VERSION ""

NS_ :

BS_:

BU_: WirelessCharger_1 WirelessChargerTemplate Applications OnBoardCharger_1 OnBoardChargerTemplate PowerModule_6 PowerModule_5 PowerModule_4 PowerModule_3 PowerModule_10 PowerModule_1 PowerModule_7 PowerModule_8 PowerModule_9 PowerModule_2 PowerModuleTemplate SystemController
VAL_TABLE_ CAN_BAUD 3 "1M" 2 "500K" 1 "250K" 0 "125K" ;
VAL_TABLE_ ConfigHwCodes 1 "P" 0 "N/A" ;
VAL_TABLE_ BL_ctrl 1 "Unlock" 0 "Reset" ;
VAL_TABLE_ BL_ACK 204 "ACK" 51 "NAK" ;
VAL_TABLE_ CalibStatus 12 "FAILED_TO_SAVE" 11 "RESET_TO_DEFAULT_VALUES" 10 "CALIBRATED" 9 "SCALE_AND_OFFSET_CALCULATED" 8 "ALL_MEASUREMENTS_GATHERED" 7 "INVALID_MEASUREMENT_POINT" 6 "V_HIGH_MEAS_GATHERED" 5 "V_LOW_MEAS_GATHERED" 3 "I_MID_MEAS_GATHERED" 4 "I_HIGH_MEAS_GATHERED" 2 "I_LOW_MEAS_GATHERED" 1 "WAITING_FOR_MEASUREMENTS" 0 "UNCALIBRATED" ;
VAL_TABLE_ CalibMeasType 1 "Current" 0 "Voltage" ;
VAL_TABLE_ OkAlert 1 "ALERT" 0 "OK" ;
VAL_TABLE_ YesNo 1 "YES" 0 "NO" ;
VAL_TABLE_ OkFault 1 "FAULT" 0 "OK" ;
VAL_TABLE_ OnOff 1 "ON" 0 "OFF" ;
VAL_TABLE_ ModuleState 16 "error" 4 "run" 1 "standby" ;
VAL_TABLE_ Status 1 "Ready" 0 "Not Ready" ;

BO_ 592 FanControl: 1 Applications
 SG_ FanControlSpeed : 0|8@1+ (1,0) [0|100] "%"  PowerModule_9,PowerModule_8,PowerModule_7,PowerModule_6,PowerModule_5,PowerModule_4,PowerModule_3,PowerModule_2,PowerModule_10,PowerModule_1,PowerModuleTemplate

BO_ 1920 Config_CAN: 1 Applications
 SG_ Config_Baud : 0|4@1+ (1,0) [0|15] "ENUM"  WirelessCharger_1,WirelessChargerTemplate

BO_ 1994 FirmwareFamilyReport_10: 4 PowerModule_10
 SG_ Firmware_Variant : 16|16@1+ (1,0) [0|0] ""  SystemController,Applications
 SG_ Firmware_Family : 0|16@1+ (1,0) [0|0] ""  SystemController,Applications

BO_ 1993 FirmwareFamilyReport_9: 4 PowerModule_9
 SG_ Firmware_Variant : 16|16@1+ (1,0) [0|0] ""  SystemController,Applications
 SG_ Firmware_Family : 0|16@1+ (1,0) [0|0] ""  SystemController,Applications

BO_ 1992 FirmwareFamilyReport_8: 4 PowerModule_8
 SG_ Firmware_Variant : 16|16@1+ (1,0) [0|0] ""  SystemController,Applications
 SG_ Firmware_Family : 0|16@1+ (1,0) [0|0] ""  SystemController,Applications

BO_ 1991 FirmwareFamilyReport_7: 4 PowerModule_7
 SG_ Firmware_Variant : 16|16@1+ (1,0) [0|0] ""  SystemController,Applications
 SG_ Firmware_Family : 0|16@1+ (1,0) [0|0] ""  SystemController,Applications

BO_ 1990 FirmwareFamilyReport_6: 4 PowerModule_6
 SG_ Firmware_Variant : 16|16@1+ (1,0) [0|0] ""  SystemController,Applications
 SG_ Firmware_Family : 0|16@1+ (1,0) [0|0] ""  SystemController,Applications

BO_ 1989 FirmwareFamilyReport_5: 4 PowerModule_5
 SG_ Firmware_Variant : 16|16@1+ (1,0) [0|0] ""  SystemController,Applications
 SG_ Firmware_Family : 0|16@1+ (1,0) [0|0] ""  SystemController,Applications

BO_ 1988 FirmwareFamilyReport_4: 4 PowerModule_4
 SG_ Firmware_Variant : 16|16@1+ (1,0) [0|0] ""  SystemController,Applications
 SG_ Firmware_Family : 0|16@1+ (1,0) [0|0] ""  SystemController,Applications

BO_ 1987 FirmwareFamilyReport_3: 4 PowerModule_3
 SG_ Firmware_Variant : 16|16@1+ (1,0) [0|0] ""  SystemController,Applications
 SG_ Firmware_Family : 0|16@1+ (1,0) [0|0] ""  SystemController,Applications

BO_ 1986 FirmwareFamilyReport_2: 4 PowerModule_2
 SG_ Firmware_Variant : 16|16@1+ (1,0) [0|0] ""  SystemController,Applications
 SG_ Firmware_Family : 0|16@1+ (1,0) [0|0] ""  SystemController,Applications

BO_ 1985 FirmwareFamilyReport_1: 4 OnBoardCharger_1
 SG_ Firmware_Variant : 16|16@1+ (1,0) [0|0] ""  SystemController,Applications
 SG_ Firmware_Family : 0|16@1+ (1,0) [0|0] ""  SystemController,Applications

BO_ 1121 ChargerTimeReport_1: 4 OnBoardCharger_1
 SG_ ChargerTimeReport : 0|32@1+ (1,0) [0|0] "seconds"  Applications

BO_ 1122 ChargerTimeReport_2: 4 Vector__XXX
 SG_ ChargerTimeReport : 0|32@1+ (1,0) [0|0] "seconds"  Applications

BO_ 1123 ChargerTimeReport_3: 4 Vector__XXX
 SG_ ChargerTimeReport : 0|32@1+ (1,0) [0|0] "seconds"  Applications

BO_ 1124 ChargerTimeReport_4: 4 Vector__XXX
 SG_ ChargerTimeReport : 0|32@1+ (1,0) [0|0] "seconds"  Applications

BO_ 1125 ChargerTimeReport_5: 4 Vector__XXX
 SG_ ChargerTimeReport : 0|32@1+ (1,0) [0|0] "seconds"  Applications

BO_ 1126 ChargerTimeReport_6: 4 Vector__XXX
 SG_ ChargerTimeReport : 0|32@1+ (1,0) [0|0] "seconds"  Applications

BO_ 1127 ChargerTimeReport_7: 4 Vector__XXX
 SG_ ChargerTimeReport : 0|32@1+ (1,0) [0|0] "seconds"  Applications

BO_ 1128 ChargerTimeReport_8: 4 Vector__XXX
 SG_ ChargerTimeReport : 0|32@1+ (1,0) [0|0] "seconds"  Applications

BO_ 1129 ChargerTimeReport_9: 4 Vector__XXX
 SG_ ChargerTimeReport : 0|32@1+ (1,0) [0|0] "seconds"  Applications

BO_ 1130 ChargerTimeReport_10: 4 Vector__XXX
 SG_ ChargerTimeReport : 0|32@1+ (1,0) [0|0] "seconds"  Applications

BO_ 1120 ChargerTimeReport_T: 4 OnBoardChargerTemplate
 SG_ ChargerTimeReport : 0|32@1+ (1,0) [0|0] "seconds" Vector__XXX

BO_ 1104 Config_SetChargerTime: 4 Applications
 SG_ ChargerTimeConfig : 0|32@1+ (1,0) [0|0] "seconds"  OnBoardCharger_1,OnBoardChargerTemplate

BO_ 1089 ProfileDeleteReport_1: 2 OnBoardCharger_1
 SG_ ProfileDeleteReport_Status : 8|8@1+ (1,0) [0|0] ""  Applications
 SG_ ProfileDeleteReport_Index : 0|8@1+ (1,0) [0|0] ""  Applications

BO_ 1090 ProfileDeleteReport_2: 2 Vector__XXX
 SG_ ProfileDeleteReport_Status : 8|8@1+ (1,0) [0|0] ""  Applications
 SG_ ProfileDeleteReport_Index : 0|8@1+ (1,0) [0|0] ""  Applications

BO_ 1091 ProfileDeleteReport_3: 2 Vector__XXX
 SG_ ProfileDeleteReport_Status : 8|8@1+ (1,0) [0|0] ""  Applications
 SG_ ProfileDeleteReport_Index : 0|8@1+ (1,0) [0|0] ""  Applications

BO_ 1092 ProfileDeleteReport_4: 2 Vector__XXX
 SG_ ProfileDeleteReport_Status : 8|8@1+ (1,0) [0|0] ""  Applications
 SG_ ProfileDeleteReport_Index : 0|8@1+ (1,0) [0|0] ""  Applications

BO_ 1093 ProfileDeleteReport_5: 2 Vector__XXX
 SG_ ProfileDeleteReport_Status : 8|8@1+ (1,0) [0|0] ""  Applications
 SG_ ProfileDeleteReport_Index : 0|8@1+ (1,0) [0|0] ""  Applications

BO_ 1094 ProfileDeleteReport_6: 2 Vector__XXX
 SG_ ProfileDeleteReport_Status : 8|8@1+ (1,0) [0|0] ""  Applications
 SG_ ProfileDeleteReport_Index : 0|8@1+ (1,0) [0|0] ""  Applications

BO_ 1095 ProfileDeleteReport_7: 2 Vector__XXX
 SG_ ProfileDeleteReport_Status : 8|8@1+ (1,0) [0|0] ""  Applications
 SG_ ProfileDeleteReport_Index : 0|8@1+ (1,0) [0|0] ""  Applications

BO_ 1096 ProfileDeleteReport_8: 2 Vector__XXX
 SG_ ProfileDeleteReport_Status : 8|8@1+ (1,0) [0|0] ""  Applications
 SG_ ProfileDeleteReport_Index : 0|8@1+ (1,0) [0|0] ""  Applications

BO_ 1097 ProfileDeleteReport_9: 2 Vector__XXX
 SG_ ProfileDeleteReport_Status : 8|8@1+ (1,0) [0|0] ""  Applications
 SG_ ProfileDeleteReport_Index : 0|8@1+ (1,0) [0|0] ""  Applications

BO_ 1098 ProfileDeleteReport_10: 2 Vector__XXX
 SG_ ProfileDeleteReport_Status : 8|8@1+ (1,0) [0|0] ""  Applications
 SG_ ProfileDeleteReport_Index : 0|8@1+ (1,0) [0|0] ""  Applications

BO_ 1088 ProfileDeleteReport_T: 2 OnBoardChargerTemplate
 SG_ ProfileDeleteReport_Status : 8|8@1+ (1,0) [0|0] "" Vector__XXX
 SG_ ProfileDeleteReport_Index : 0|8@1+ (1,0) [0|0] "" Vector__XXX

BO_ 1072 ProfileDeleteRequest: 1 Applications
 SG_ ProfileDelete_Index : 0|8@1+ (1,0) [0|0] ""  OnBoardCharger_1,OnBoardChargerTemplate

BO_ 1057 ProfileIdReport_1: 7 OnBoardCharger_1
 SG_ ProfileReport_Status : 0|8@1+ (1,0) [0|0] ""  Applications
 SG_ ProfileReport_MaxIndex : 16|8@1+ (1,0) [0|0] ""  Applications
 SG_ ProfileReport_Index : 8|8@1+ (1,0) [0|0] ""  Applications
 SG_ ProfileReport_Id : 24|32@1+ (1,0) [0|0] ""  Applications

BO_ 1058 ProfileIdReport_2: 7 Vector__XXX
 SG_ ProfileReport_Status : 0|8@1+ (1,0) [0|0] ""  Applications
 SG_ ProfileReport_MaxIndex : 16|8@1+ (1,0) [0|0] ""  Applications
 SG_ ProfileReport_Index : 8|8@1+ (1,0) [0|0] ""  Applications
 SG_ ProfileReport_Id : 24|32@1+ (1,0) [0|0] ""  Applications

BO_ 1059 ProfileIdReport_3: 7 Vector__XXX
 SG_ ProfileReport_Status : 0|8@1+ (1,0) [0|0] ""  Applications
 SG_ ProfileReport_MaxIndex : 16|8@1+ (1,0) [0|0] ""  Applications
 SG_ ProfileReport_Index : 8|8@1+ (1,0) [0|0] ""  Applications
 SG_ ProfileReport_Id : 24|32@1+ (1,0) [0|0] ""  Applications

BO_ 1060 ProfileIdReport_4: 7 Vector__XXX
 SG_ ProfileReport_Status : 0|8@1+ (1,0) [0|0] ""  Applications
 SG_ ProfileReport_MaxIndex : 16|8@1+ (1,0) [0|0] ""  Applications
 SG_ ProfileReport_Index : 8|8@1+ (1,0) [0|0] ""  Applications
 SG_ ProfileReport_Id : 24|32@1+ (1,0) [0|0] ""  Applications

BO_ 1061 ProfileIdReport_5: 7 Vector__XXX
 SG_ ProfileReport_Status : 0|8@1+ (1,0) [0|0] ""  Applications
 SG_ ProfileReport_MaxIndex : 16|8@1+ (1,0) [0|0] ""  Applications
 SG_ ProfileReport_Index : 8|8@1+ (1,0) [0|0] ""  Applications
 SG_ ProfileReport_Id : 24|32@1+ (1,0) [0|0] ""  Applications

BO_ 1062 ProfileIdReport_6: 7 Vector__XXX
 SG_ ProfileReport_Status : 0|8@1+ (1,0) [0|0] ""  Applications
 SG_ ProfileReport_MaxIndex : 16|8@1+ (1,0) [0|0] ""  Applications
 SG_ ProfileReport_Index : 8|8@1+ (1,0) [0|0] ""  Applications
 SG_ ProfileReport_Id : 24|32@1+ (1,0) [0|0] ""  Applications

BO_ 1063 ProfileIdReport_7: 7 Vector__XXX
 SG_ ProfileReport_Status : 0|8@1+ (1,0) [0|0] ""  Applications
 SG_ ProfileReport_MaxIndex : 16|8@1+ (1,0) [0|0] ""  Applications
 SG_ ProfileReport_Index : 8|8@1+ (1,0) [0|0] ""  Applications
 SG_ ProfileReport_Id : 24|32@1+ (1,0) [0|0] ""  Applications

BO_ 1064 ProfileIdReport_8: 7 Vector__XXX
 SG_ ProfileReport_Status : 0|8@1+ (1,0) [0|0] ""  Applications
 SG_ ProfileReport_MaxIndex : 16|8@1+ (1,0) [0|0] ""  Applications
 SG_ ProfileReport_Index : 8|8@1+ (1,0) [0|0] ""  Applications
 SG_ ProfileReport_Id : 24|32@1+ (1,0) [0|0] ""  Applications

BO_ 1065 ProfileIdReport_9: 7 Vector__XXX
 SG_ ProfileReport_Status : 0|8@1+ (1,0) [0|0] ""  Applications
 SG_ ProfileReport_MaxIndex : 16|8@1+ (1,0) [0|0] ""  Applications
 SG_ ProfileReport_Index : 8|8@1+ (1,0) [0|0] ""  Applications
 SG_ ProfileReport_Id : 24|32@1+ (1,0) [0|0] ""  Applications

BO_ 1066 ProfileIdReport_10: 7 Vector__XXX
 SG_ ProfileReport_Status : 0|8@1+ (1,0) [0|0] ""  Applications
 SG_ ProfileReport_MaxIndex : 16|8@1+ (1,0) [0|0] ""  Applications
 SG_ ProfileReport_Index : 8|8@1+ (1,0) [0|0] ""  Applications
 SG_ ProfileReport_Id : 24|32@1+ (1,0) [0|0] ""  Applications

BO_ 1056 ProfileIdReport_T: 7 OnBoardChargerTemplate
 SG_ ProfileReport_Status : 0|8@1+ (1,0) [0|0] "" Vector__XXX
 SG_ ProfileReport_MaxIndex : 16|8@1+ (1,0) [0|0] "" Vector__XXX
 SG_ ProfileReport_Index : 8|8@1+ (1,0) [0|0] "" Vector__XXX
 SG_ ProfileReport_Id : 24|32@1+ (1,0) [0|0] "" Vector__XXX

BO_ 1040 ProfileIdRequest: 1 Applications
 SG_ ProfileRequest_Index : 0|8@1+ (1,0) [0|0] ""  WirelessCharger_1,WirelessChargerTemplate,OnBoardCharger_1,OnBoardChargerTemplate

BO_ 586 PingAck_10: 1 PowerModule_10
 SG_ PingAck_Data : 0|8@1+ (1,0) [0|0] ""  SystemController,Applications

BO_ 585 PingAck_9: 1 PowerModule_9
 SG_ PingAck_Data : 0|8@1+ (1,0) [0|0] ""  SystemController,Applications

BO_ 584 PingAck_8: 1 PowerModule_8
 SG_ PingAck_Data : 0|8@1+ (1,0) [0|0] ""  SystemController,Applications

BO_ 583 PingAck_7: 1 PowerModule_7
 SG_ PingAck_Data : 0|8@1+ (1,0) [0|0] ""  SystemController,Applications

BO_ 582 PingAck_6: 1 PowerModule_6
 SG_ PingAck_Data : 0|8@1+ (1,0) [0|0] ""  SystemController,Applications

BO_ 581 PingAck_5: 1 PowerModule_5
 SG_ PingAck_Data : 0|8@1+ (1,0) [0|0] ""  SystemController,Applications

BO_ 580 PingAck_4: 1 PowerModule_4
 SG_ PingAck_Data : 0|8@1+ (1,0) [0|0] ""  SystemController,Applications

BO_ 579 PingAck_3: 1 PowerModule_3
 SG_ PingAck_Data : 0|8@1+ (1,0) [0|0] ""  SystemController,Applications

BO_ 578 PingAck_2: 1 PowerModule_2
 SG_ PingAck_Data : 0|8@1+ (1,0) [0|0] ""  SystemController,Applications

BO_ 577 PingAck_1: 1 OnBoardCharger_1
 SG_ PingAck_Data : 0|8@1+ (1,0) [0|0] ""  SystemController,Applications

BO_ 576 PingAck_T: 1 OnBoardChargerTemplate
 SG_ PingAck_Data : 0|8@1+ (1,0) [0|0] "" Vector__XXX

BO_ 560 PingCmd: 1 Applications
 SG_ PingCmd_Data : 0|8@1+ (1,0) [0|0] ""  WirelessCharger_1,PowerModule_9,PowerModule_8,PowerModule_7,PowerModule_6,PowerModule_5,PowerModule_4,PowerModule_3,PowerModule_2,PowerModule_10,PowerModule_1,WirelessChargerTemplate,PowerModuleTemplate,OnBoardCharger_1,OnBoardChargerTemplate

BO_ 1984 FirmwareFamilyReport_T: 4 OnBoardChargerTemplate
 SG_ Firmware_Variant : 16|16@1+ (1,0) [0|0] "" Vector__XXX
 SG_ Firmware_Family : 0|16@1+ (1,0) [0|0] "" Vector__XXX

BO_ 1009 TemperatureMeasurements_1: 4 WirelessCharger_1
 SG_ Report_Temperature_2 : 16|16@1- (0.005,0) [-163.84|163.835] "C"  Applications
 SG_ Report_Temperature_1 : 0|16@1- (0.005,0) [-163.84|163.835] "C"  Applications

BO_ 1010 TemperatureMeasurements_2: 4 Vector__XXX
 SG_ Report_Temperature_2 : 16|16@1- (0.005,0) [-163.84|163.835] "C"  Applications
 SG_ Report_Temperature_1 : 0|16@1- (0.005,0) [-163.84|163.835] "C"  Applications

BO_ 1011 TemperatureMeasurements_3: 4 Vector__XXX
 SG_ Report_Temperature_2 : 16|16@1- (0.005,0) [-163.84|163.835] "C"  Applications
 SG_ Report_Temperature_1 : 0|16@1- (0.005,0) [-163.84|163.835] "C"  Applications

BO_ 1012 TemperatureMeasurements_4: 4 Vector__XXX
 SG_ Report_Temperature_2 : 16|16@1- (0.005,0) [-163.84|163.835] "C"  Applications
 SG_ Report_Temperature_1 : 0|16@1- (0.005,0) [-163.84|163.835] "C"  Applications

BO_ 1013 TemperatureMeasurements_5: 4 Vector__XXX
 SG_ Report_Temperature_2 : 16|16@1- (0.005,0) [-163.84|163.835] "C"  Applications
 SG_ Report_Temperature_1 : 0|16@1- (0.005,0) [-163.84|163.835] "C"  Applications

BO_ 1014 TemperatureMeasurements_6: 4 Vector__XXX
 SG_ Report_Temperature_2 : 16|16@1- (0.005,0) [-163.84|163.835] "C"  Applications
 SG_ Report_Temperature_1 : 0|16@1- (0.005,0) [-163.84|163.835] "C"  Applications

BO_ 1015 TemperatureMeasurements_7: 4 Vector__XXX
 SG_ Report_Temperature_2 : 16|16@1- (0.005,0) [-163.84|163.835] "C"  Applications
 SG_ Report_Temperature_1 : 0|16@1- (0.005,0) [-163.84|163.835] "C"  Applications

BO_ 1016 TemperatureMeasurements_8: 4 Vector__XXX
 SG_ Report_Temperature_2 : 16|16@1- (0.005,0) [-163.84|163.835] "C"  Applications
 SG_ Report_Temperature_1 : 0|16@1- (0.005,0) [-163.84|163.835] "C"  Applications

BO_ 1017 TemperatureMeasurements_9: 4 Vector__XXX
 SG_ Report_Temperature_2 : 16|16@1- (0.005,0) [-163.84|163.835] "C"  Applications
 SG_ Report_Temperature_1 : 0|16@1- (0.005,0) [-163.84|163.835] "C"  Applications

BO_ 1018 TemperatureMeasurements_10: 4 Vector__XXX
 SG_ Report_Temperature_2 : 16|16@1- (0.005,0) [-163.84|163.835] "C"  Applications
 SG_ Report_Temperature_1 : 0|16@1- (0.005,0) [-163.84|163.835] "C"  Applications

BO_ 1008 TemperatureMeasurementsT: 4 WirelessChargerTemplate
 SG_ Report_Temperature_2 : 16|16@1- (0.005,0) [-163.84|163.835] "C" Vector__XXX
 SG_ Report_Temperature_1 : 0|16@1- (0.005,0) [-163.84|163.835] "C" Vector__XXX

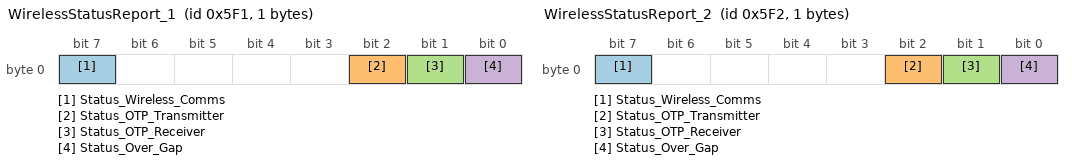
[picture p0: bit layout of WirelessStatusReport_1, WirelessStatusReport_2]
BO_ 1521 WirelessStatusReport_1: 1 WirelessCharger_1
 SG_ Status_Wireless_Comms : 7|1@1+ (1,0) [0|1] ""  Applications
 SG_ Status_OTP_Transmitter : 2|1@1+ (1,0) [0|1] ""  Applications
 SG_ Status_OTP_Receiver : 1|1@1+ (1,0) [0|1] ""  Applications
 SG_ Status_Over_Gap : 0|1@1+ (1,0) [0|1] ""  Applications

BO_ 1522 WirelessStatusReport_2: 1 Vector__XXX
 SG_ Status_Wireless_Comms : 7|1@1+ (1,0) [0|1] ""  Applications
 SG_ Status_OTP_Transmitter : 2|1@1+ (1,0) [0|1] ""  Applications
 SG_ Status_OTP_Receiver : 1|1@1+ (1,0) [0|1] ""  Applications
 SG_ Status_Over_Gap : 0|1@1+ (1,0) [0|1] ""  Applications

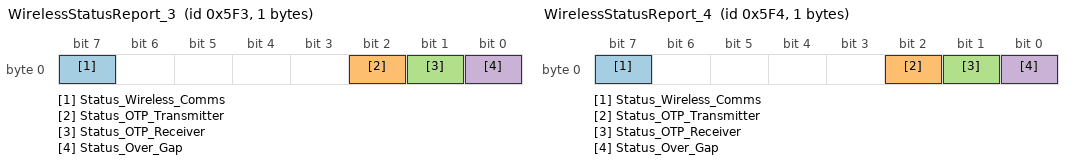
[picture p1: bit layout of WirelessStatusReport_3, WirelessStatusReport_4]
BO_ 1523 WirelessStatusReport_3: 1 Vector__XXX
 SG_ Status_Wireless_Comms : 7|1@1+ (1,0) [0|1] ""  Applications
 SG_ Status_OTP_Transmitter : 2|1@1+ (1,0) [0|1] ""  Applications
 SG_ Status_OTP_Receiver : 1|1@1+ (1,0) [0|1] ""  Applications
 SG_ Status_Over_Gap : 0|1@1+ (1,0) [0|1] ""  Applications

BO_ 1524 WirelessStatusReport_4: 1 Vector__XXX
 SG_ Status_Wireless_Comms : 7|1@1+ (1,0) [0|1] ""  Applications
 SG_ Status_OTP_Transmitter : 2|1@1+ (1,0) [0|1] ""  Applications
 SG_ Status_OTP_Receiver : 1|1@1+ (1,0) [0|1] ""  Applications
 SG_ Status_Over_Gap : 0|1@1+ (1,0) [0|1] ""  Applications

BO_ 1525 WirelessStatusReport_5: 1 Vector__XXX
 SG_ Status_Wireless_Comms : 7|1@1+ (1,0) [0|1] ""  Applications
 SG_ Status_OTP_Transmitter : 2|1@1+ (1,0) [0|1] ""  Applications
 SG_ Status_OTP_Receiver : 1|1@1+ (1,0) [0|1] ""  Applications
 SG_ Status_Over_Gap : 0|1@1+ (1,0) [0|1] ""  Applications

BO_ 1526 WirelessStatusReport_6: 1 Vector__XXX
 SG_ Status_Wireless_Comms : 7|1@1+ (1,0) [0|1] ""  Applications
 SG_ Status_OTP_Transmitter : 2|1@1+ (1,0) [0|1] ""  Applications
 SG_ Status_OTP_Receiver : 1|1@1+ (1,0) [0|1] ""  Applications
 SG_ Status_Over_Gap : 0|1@1+ (1,0) [0|1] ""  Applications

BO_ 1527 WirelessStatusReport_7: 1 Vector__XXX
 SG_ Status_Wireless_Comms : 7|1@1+ (1,0) [0|1] ""  Applications
 SG_ Status_OTP_Transmitter : 2|1@1+ (1,0) [0|1] ""  Applications
 SG_ Status_OTP_Receiver : 1|1@1+ (1,0) [0|1] ""  Applications
 SG_ Status_Over_Gap : 0|1@1+ (1,0) [0|1] ""  Applications

BO_ 1528 WirelessStatusReport_8: 1 Vector__XXX
 SG_ Status_Wireless_Comms : 7|1@1+ (1,0) [0|1] ""  Applications
 SG_ Status_OTP_Transmitter : 2|1@1+ (1,0) [0|1] ""  Applications
 SG_ Status_OTP_Receiver : 1|1@1+ (1,0) [0|1] ""  Applications
 SG_ Status_Over_Gap : 0|1@1+ (1,0) [0|1] ""  Applications

BO_ 1529 WirelessStatusReport_9: 1 Vector__XXX
 SG_ Status_Wireless_Comms : 7|1@1+ (1,0) [0|1] ""  Applications
 SG_ Status_OTP_Transmitter : 2|1@1+ (1,0) [0|1] ""  Applications
 SG_ Status_OTP_Receiver : 1|1@1+ (1,0) [0|1] ""  Applications
 SG_ Status_Over_Gap : 0|1@1+ (1,0) [0|1] ""  Applications

BO_ 1530 WirelessStatusReport_10: 1 Vector__XXX
 SG_ Status_Wireless_Comms : 7|1@1+ (1,0) [0|1] ""  Applications
 SG_ Status_OTP_Transmitter : 2|1@1+ (1,0) [0|1] ""  Applications
 SG_ Status_OTP_Receiver : 1|1@1+ (1,0) [0|1] ""  Applications
 SG_ Status_Over_Gap : 0|1@1+ (1,0) [0|1] ""  Applications

BO_ 1520 WirelessStatusReportT: 1 WirelessChargerTemplate
 SG_ Status_Wireless_Comms : 7|1@1+ (1,0) [0|1] "" Vector__XXX
 SG_ Status_OTP_Transmitter : 2|1@1+ (1,0) [0|1] "" Vector__XXX
 SG_ Status_OTP_Receiver : 1|1@1+ (1,0) [0|1] "" Vector__XXX
 SG_ Status_Over_Gap : 0|1@1+ (1,0) [0|1] "" Vector__XXX

BO_ 1889 Calibration_CoefficientReport_1: 8 WirelessCharger_1
 SG_ Cabli_Threshold : 48|16@1- (1,0) [0|0] ""  Applications
 SG_ Cabli_Offset : 32|16@1- (1,0) [0|0] ""  Applications
 SG_ Cabli_Amp : 16|16@1- (1,0) [0|0] ""  Applications
 SG_ Calib_Line : 8|8@1+ (1,0) [0|0] ""  Applications
 SG_ Calib_Mode : 0|8@1+ (1,0) [0|0] ""  Applications

BO_ 1890 Calibration_CoefficientReport_2: 8 Vector__XXX
 SG_ Cabli_Threshold : 48|16@1- (1,0) [0|0] ""  Applications
 SG_ Cabli_Offset : 32|16@1- (1,0) [0|0] ""  Applications
 SG_ Cabli_Amp : 16|16@1- (1,0) [0|0] ""  Applications
 SG_ Calib_Line : 8|8@1+ (1,0) [0|0] ""  Applications
 SG_ Calib_Mode : 0|8@1+ (1,0) [0|0] ""  Applications

BO_ 1891 Calibration_CoefficientReport_3: 8 Vector__XXX
 SG_ Cabli_Threshold : 48|16@1- (1,0) [0|0] ""  Applications
 SG_ Cabli_Offset : 32|16@1- (1,0) [0|0] ""  Applications
 SG_ Cabli_Amp : 16|16@1- (1,0) [0|0] ""  Applications
 SG_ Calib_Line : 8|8@1+ (1,0) [0|0] ""  Applications
 SG_ Calib_Mode : 0|8@1+ (1,0) [0|0] ""  Applications

BO_ 1892 Calibration_CoefficientReport_4: 8 Vector__XXX
 SG_ Cabli_Threshold : 48|16@1- (1,0) [0|0] ""  Applications
 SG_ Cabli_Offset : 32|16@1- (1,0) [0|0] ""  Applications
 SG_ Cabli_Amp : 16|16@1- (1,0) [0|0] ""  Applications
 SG_ Calib_Line : 8|8@1+ (1,0) [0|0] ""  Applications
 SG_ Calib_Mode : 0|8@1+ (1,0) [0|0] ""  Applications

BO_ 1893 Calibration_CoefficientReport_5: 8 Vector__XXX
 SG_ Cabli_Threshold : 48|16@1- (1,0) [0|0] ""  Applications
 SG_ Cabli_Offset : 32|16@1- (1,0) [0|0] ""  Applications
 SG_ Cabli_Amp : 16|16@1- (1,0) [0|0] ""  Applications
 SG_ Calib_Line : 8|8@1+ (1,0) [0|0] ""  Applications
 SG_ Calib_Mode : 0|8@1+ (1,0) [0|0] ""  Applications

BO_ 1894 Calibration_CoefficientReport_6: 8 Vector__XXX
 SG_ Cabli_Threshold : 48|16@1- (1,0) [0|0] ""  Applications
 SG_ Cabli_Offset : 32|16@1- (1,0) [0|0] ""  Applications
 SG_ Cabli_Amp : 16|16@1- (1,0) [0|0] ""  Applications
 SG_ Calib_Line : 8|8@1+ (1,0) [0|0] ""  Applications
 SG_ Calib_Mode : 0|8@1+ (1,0) [0|0] ""  Applications

BO_ 1895 Calibration_CoefficientReport_7: 8 Vector__XXX
 SG_ Cabli_Threshold : 48|16@1- (1,0) [0|0] ""  Applications
 SG_ Cabli_Offset : 32|16@1- (1,0) [0|0] ""  Applications
 SG_ Cabli_Amp : 16|16@1- (1,0) [0|0] ""  Applications
 SG_ Calib_Line : 8|8@1+ (1,0) [0|0] ""  Applications
 SG_ Calib_Mode : 0|8@1+ (1,0) [0|0] ""  Applications

BO_ 1896 Calibration_CoefficientReport_8: 8 Vector__XXX
 SG_ Cabli_Threshold : 48|16@1- (1,0) [0|0] ""  Applications
 SG_ Cabli_Offset : 32|16@1- (1,0) [0|0] ""  Applications
 SG_ Cabli_Amp : 16|16@1- (1,0) [0|0] ""  Applications
 SG_ Calib_Line : 8|8@1+ (1,0) [0|0] ""  Applications
 SG_ Calib_Mode : 0|8@1+ (1,0) [0|0] ""  Applications

BO_ 1897 Calibration_CoefficientReport_9: 8 Vector__XXX
 SG_ Cabli_Threshold : 48|16@1- (1,0) [0|0] ""  Applications
 SG_ Cabli_Offset : 32|16@1- (1,0) [0|0] ""  Applications
 SG_ Cabli_Amp : 16|16@1- (1,0) [0|0] ""  Applications
 SG_ Calib_Line : 8|8@1+ (1,0) [0|0] ""  Applications
 SG_ Calib_Mode : 0|8@1+ (1,0) [0|0] ""  Applications

BO_ 1898 Calibration_CoefficientReport_10: 8 Vector__XXX
 SG_ Cabli_Threshold : 48|16@1- (1,0) [0|0] ""  Applications
 SG_ Cabli_Offset : 32|16@1- (1,0) [0|0] ""  Applications
 SG_ Cabli_Amp : 16|16@1- (1,0) [0|0] ""  Applications
 SG_ Calib_Line : 8|8@1+ (1,0) [0|0] ""  Applications
 SG_ Calib_Mode : 0|8@1+ (1,0) [0|0] ""  Applications

BO_ 1888 Calibration_CoefficientReportT: 8 WirelessChargerTemplate
 SG_ Cabli_Threshold : 48|16@1- (1,0) [0|0] "" Vector__XXX
 SG_ Cabli_Offset : 32|16@1- (1,0) [0|0] "" Vector__XXX
 SG_ Cabli_Amp : 16|16@1- (1,0) [0|0] "" Vector__XXX
 SG_ Calib_Line : 8|8@1+ (1,0) [0|0] "" Vector__XXX
 SG_ Calib_Mode : 0|8@1+ (1,0) [0|0] "" Vector__XXX

BO_ 1600 Calibration_CoefficientRead: 2 Applications
 SG_ Calib_Line_R : 8|8@1+ (1,0) [0|0] ""  WirelessCharger_1,WirelessChargerTemplate
 SG_ Calib_Mode_R : 0|8@1+ (1,0) [0|0] ""  WirelessCharger_1,WirelessChargerTemplate

BO_ 1536 Calibration_MeasurementGet: 1 Applications
 SG_ Calib_MeasurementType : 0|8@1+ (1,0) [0|0] ""  WirelessCharger_1,WirelessChargerTemplate

BO_ 1584 Calibration_CoefficientSet: 8 Applications
 SG_ Cabli_Threshold : 48|16@1- (1,0) [0|0] ""  WirelessCharger_1,WirelessChargerTemplate
 SG_ Cabli_Offset : 32|16@1- (1,0) [0|0] ""  WirelessCharger_1,WirelessChargerTemplate
 SG_ Cabli_Amp : 16|16@1- (1,0) [0|0] ""  WirelessCharger_1,WirelessChargerTemplate
 SG_ Calib_Line : 8|8@1+ (1,0) [0|0] ""  WirelessCharger_1,WirelessChargerTemplate
 SG_ Calib_Mode : 0|8@1+ (1,0) [0|0] ""  WirelessCharger_1,WirelessChargerTemplate

BO_ 993 WirelessStatusMeasurements_1: 5 WirelessCharger_1
 SG_ Report_Meas_Gap : 32|8@1+ (1,0) [0|255] "mm"  Applications
 SG_ Report_Meas_Charger_Efficient : 16|10@1+ (0.1,0) [0|100] "%"  Applications
 SG_ Report_Meas_SOC : 0|10@1+ (0.1,0) [0|100] "%"  Applications

BO_ 994 WirelessStatusMeasurements_2: 5 Vector__XXX
 SG_ Report_Meas_Gap : 32|8@1+ (1,0) [0|255] "mm"  Applications
 SG_ Report_Meas_Charger_Efficient : 16|10@1+ (0.1,0) [0|100] "%"  Applications
 SG_ Report_Meas_SOC : 0|10@1+ (0.1,0) [0|100] "%"  Applications

BO_ 995 WirelessStatusMeasurements_3: 5 Vector__XXX
 SG_ Report_Meas_Gap : 32|8@1+ (1,0) [0|255] "mm"  Applications
 SG_ Report_Meas_Charger_Efficient : 16|10@1+ (0.1,0) [0|100] "%"  Applications
 SG_ Report_Meas_SOC : 0|10@1+ (0.1,0) [0|100] "%"  Applications

BO_ 996 WirelessStatusMeasurements_4: 5 Vector__XXX
 SG_ Report_Meas_Gap : 32|8@1+ (1,0) [0|255] "mm"  Applications
 SG_ Report_Meas_Charger_Efficient : 16|10@1+ (0.1,0) [0|100] "%"  Applications
 SG_ Report_Meas_SOC : 0|10@1+ (0.1,0) [0|100] "%"  Applications

BO_ 997 WirelessStatusMeasurements_5: 5 Vector__XXX
 SG_ Report_Meas_Gap : 32|8@1+ (1,0) [0|255] "mm"  Applications
 SG_ Report_Meas_Charger_Efficient : 16|10@1+ (0.1,0) [0|100] "%"  Applications
 SG_ Report_Meas_SOC : 0|10@1+ (0.1,0) [0|100] "%"  Applications

BO_ 998 WirelessStatusMeasurements_6: 5 Vector__XXX
 SG_ Report_Meas_Gap : 32|8@1+ (1,0) [0|255] "mm"  Applications
 SG_ Report_Meas_Charger_Efficient : 16|10@1+ (0.1,0) [0|100] "%"  Applications
 SG_ Report_Meas_SOC : 0|10@1+ (0.1,0) [0|100] "%"  Applications

BO_ 999 WirelessStatusMeasurements_7: 5 Vector__XXX
 SG_ Report_Meas_Gap : 32|8@1+ (1,0) [0|255] "mm"  Applications
 SG_ Report_Meas_Charger_Efficient : 16|10@1+ (0.1,0) [0|100] "%"  Applications
 SG_ Report_Meas_SOC : 0|10@1+ (0.1,0) [0|100] "%"  Applications

BO_ 1000 WirelessStatusMeasurements_8: 5 Vector__XXX
 SG_ Report_Meas_Gap : 32|8@1+ (1,0) [0|255] "mm"  Applications
 SG_ Report_Meas_Charger_Efficient : 16|10@1+ (0.1,0) [0|100] "%"  Applications
 SG_ Report_Meas_SOC : 0|10@1+ (0.1,0) [0|100] "%"  Applications

BO_ 1001 WirelessStatusMeasurements_9: 5 Vector__XXX
 SG_ Report_Meas_Gap : 32|8@1+ (1,0) [0|255] "mm"  Applications
 SG_ Report_Meas_Charger_Efficient : 16|10@1+ (0.1,0) [0|100] "%"  Applications
 SG_ Report_Meas_SOC : 0|10@1+ (0.1,0) [0|100] "%"  Applications

BO_ 1002 WirelessStatusMeasurements_10: 5 Vector__XXX
 SG_ Report_Meas_Gap : 32|8@1+ (1,0) [0|255] "mm"  Applications
 SG_ Report_Meas_Charger_Efficient : 16|10@1+ (0.1,0) [0|100] "%"  Applications
 SG_ Report_Meas_SOC : 0|10@1+ (0.1,0) [0|100] "%"  Applications

BO_ 992 WirelessStatusMeasurementsT: 5 WirelessChargerTemplate
 SG_ Report_Meas_Gap : 32|8@1+ (1,0) [0|255] "mm" Vector__XXX
 SG_ Report_Meas_Charger_Efficient : 16|10@1+ (0.1,0) [0|100] "%" Vector__XXX
 SG_ Report_Meas_SOC : 0|10@1+ (0.1,0) [0|100] "%" Vector__XXX

BO_ 1776 Config_SetWLComCfg: 5 Applications
 SG_ Config_SetWLComPassword : 8|32@1+ (1,0) [0|0] "" Vector__XXX
 SG_ Config_SetWLComId : 0|8@1+ (1,0) [0|0] "" Vector__XXX

BO_ 1905 Control_ReportCommInfo_1: 8 WirelessCharger_1
 SG_ Ctrl_CommLQI : 56|8@1+ (1,0) [0|0] ""  Applications
 SG_ Ctrl_CommRssi : 48|8@1+ (1,0) [0|0] ""  Applications
 SG_ Ctrl_CommSuccessRate : 16|32@1+ (1,0) [0|0] "0.000001"  Applications
 SG_ Ctrl_CommId : 8|8@1+ (1,0) [0|0] ""  Applications
 SG_ Ctrl_CommChannel : 0|8@1+ (1,0) [0|0] ""  Applications

BO_ 1906 Control_ReportCommInfo_2: 8 Vector__XXX
 SG_ Ctrl_CommLQI : 56|8@1+ (1,0) [0|0] ""  Applications
 SG_ Ctrl_CommRssi : 48|8@1+ (1,0) [0|0] ""  Applications
 SG_ Ctrl_CommSuccessRate : 16|32@1+ (1,0) [0|0] "0.000001"  Applications
 SG_ Ctrl_CommId : 8|8@1+ (1,0) [0|0] ""  Applications
 SG_ Ctrl_CommChannel : 0|8@1+ (1,0) [0|0] ""  Applications

BO_ 1907 Control_ReportCommInfo_3: 8 Vector__XXX
 SG_ Ctrl_CommLQI : 56|8@1+ (1,0) [0|0] ""  Applications
 SG_ Ctrl_CommRssi : 48|8@1+ (1,0) [0|0] ""  Applications
 SG_ Ctrl_CommSuccessRate : 16|32@1+ (1,0) [0|0] "0.000001"  Applications
 SG_ Ctrl_CommId : 8|8@1+ (1,0) [0|0] ""  Applications
 SG_ Ctrl_CommChannel : 0|8@1+ (1,0) [0|0] ""  Applications

BO_ 1908 Control_ReportCommInfo_4: 8 Vector__XXX
 SG_ Ctrl_CommLQI : 56|8@1+ (1,0) [0|0] ""  Applications
 SG_ Ctrl_CommRssi : 48|8@1+ (1,0) [0|0] ""  Applications
 SG_ Ctrl_CommSuccessRate : 16|32@1+ (1,0) [0|0] "0.000001"  Applications
 SG_ Ctrl_CommId : 8|8@1+ (1,0) [0|0] ""  Applications
 SG_ Ctrl_CommChannel : 0|8@1+ (1,0) [0|0] ""  Applications

BO_ 1909 Control_ReportCommInfo_5: 8 Vector__XXX
 SG_ Ctrl_CommLQI : 56|8@1+ (1,0) [0|0] ""  Applications
 SG_ Ctrl_CommRssi : 48|8@1+ (1,0) [0|0] ""  Applications
 SG_ Ctrl_CommSuccessRate : 16|32@1+ (1,0) [0|0] "0.000001"  Applications
 SG_ Ctrl_CommId : 8|8@1+ (1,0) [0|0] ""  Applications
 SG_ Ctrl_CommChannel : 0|8@1+ (1,0) [0|0] ""  Applications

BO_ 1910 Control_ReportCommInfo_6: 8 Vector__XXX
 SG_ Ctrl_CommLQI : 56|8@1+ (1,0) [0|0] ""  Applications
 SG_ Ctrl_CommRssi : 48|8@1+ (1,0) [0|0] ""  Applications
 SG_ Ctrl_CommSuccessRate : 16|32@1+ (1,0) [0|0] "0.000001"  Applications
 SG_ Ctrl_CommId : 8|8@1+ (1,0) [0|0] ""  Applications
 SG_ Ctrl_CommChannel : 0|8@1+ (1,0) [0|0] ""  Applications

BO_ 1911 Control_ReportCommInfo_7: 8 Vector__XXX
 SG_ Ctrl_CommLQI : 56|8@1+ (1,0) [0|0] ""  Applications
 SG_ Ctrl_CommRssi : 48|8@1+ (1,0) [0|0] ""  Applications
 SG_ Ctrl_CommSuccessRate : 16|32@1+ (1,0) [0|0] "0.000001"  Applications
 SG_ Ctrl_CommId : 8|8@1+ (1,0) [0|0] ""  Applications
 SG_ Ctrl_CommChannel : 0|8@1+ (1,0) [0|0] ""  Applications

BO_ 1912 Control_ReportCommInfo_8: 8 Vector__XXX
 SG_ Ctrl_CommLQI : 56|8@1+ (1,0) [0|0] ""  Applications
 SG_ Ctrl_CommRssi : 48|8@1+ (1,0) [0|0] ""  Applications
 SG_ Ctrl_CommSuccessRate : 16|32@1+ (1,0) [0|0] "0.000001"  Applications
 SG_ Ctrl_CommId : 8|8@1+ (1,0) [0|0] ""  Applications
 SG_ Ctrl_CommChannel : 0|8@1+ (1,0) [0|0] ""  Applications

BO_ 1913 Control_ReportCommInfo_9: 8 Vector__XXX
 SG_ Ctrl_CommLQI : 56|8@1+ (1,0) [0|0] ""  Applications
 SG_ Ctrl_CommRssi : 48|8@1+ (1,0) [0|0] ""  Applications
 SG_ Ctrl_CommSuccessRate : 16|32@1+ (1,0) [0|0] "0.000001"  Applications
 SG_ Ctrl_CommId : 8|8@1+ (1,0) [0|0] ""  Applications
 SG_ Ctrl_CommChannel : 0|8@1+ (1,0) [0|0] ""  Applications

BO_ 1914 Control_ReportCommInfo_10: 8 Vector__XXX
 SG_ Ctrl_CommLQI : 56|8@1+ (1,0) [0|0] ""  Applications
 SG_ Ctrl_CommRssi : 48|8@1+ (1,0) [0|0] ""  Applications
 SG_ Ctrl_CommSuccessRate : 16|32@1+ (1,0) [0|0] "0.000001"  Applications
 SG_ Ctrl_CommId : 8|8@1+ (1,0) [0|0] ""  Applications
 SG_ Ctrl_CommChannel : 0|8@1+ (1,0) [0|0] ""  Applications

BO_ 1904 Control_ReportCommInfo_T: 8 WirelessChargerTemplate
 SG_ Ctrl_CommLQI : 56|8@1+ (1,0) [0|0] "" Vector__XXX
 SG_ Ctrl_CommRssi : 48|8@1+ (1,0) [0|0] "" Vector__XXX
 SG_ Ctrl_CommSuccessRate : 16|32@1+ (1,0) [0|0] "0.000001" Vector__XXX
 SG_ Ctrl_CommId : 8|8@1+ (1,0) [0|0] "" Vector__XXX
 SG_ Ctrl_CommChannel : 0|8@1+ (1,0) [0|0] "" Vector__XXX

BO_ 769 Control_RdReg_Ack_1: 4 WirelessCharger_1
 SG_ Ctrl_RdReg_Value : 0|32@1+ (1,0) [0|0] ""  Applications

BO_ 770 Control_RdReg_Ack_2: 4 Vector__XXX
 SG_ Ctrl_RdReg_Value : 0|32@1+ (1,0) [0|0] ""  Applications

BO_ 771 Control_RdReg_Ack_3: 4 Vector__XXX
 SG_ Ctrl_RdReg_Value : 0|32@1+ (1,0) [0|0] ""  Applications

BO_ 772 Control_RdReg_Ack_4: 4 Vector__XXX
 SG_ Ctrl_RdReg_Value : 0|32@1+ (1,0) [0|0] ""  Applications

BO_ 773 Control_RdReg_Ack_5: 4 Vector__XXX
 SG_ Ctrl_RdReg_Value : 0|32@1+ (1,0) [0|0] ""  Applications

BO_ 774 Control_RdReg_Ack_6: 4 Vector__XXX
 SG_ Ctrl_RdReg_Value : 0|32@1+ (1,0) [0|0] ""  Applications

BO_ 775 Control_RdReg_Ack_7: 4 Vector__XXX
 SG_ Ctrl_RdReg_Value : 0|32@1+ (1,0) [0|0] ""  Applications

BO_ 776 Control_RdReg_Ack_8: 4 Vector__XXX
 SG_ Ctrl_RdReg_Value : 0|32@1+ (1,0) [0|0] ""  Applications

BO_ 777 Control_RdReg_Ack_9: 4 Vector__XXX
 SG_ Ctrl_RdReg_Value : 0|32@1+ (1,0) [0|0] ""  Applications

BO_ 778 Control_RdReg_Ack_10: 4 Vector__XXX
 SG_ Ctrl_RdReg_Value : 0|32@1+ (1,0) [0|0] ""  Applications

BO_ 768 Control_RdReg_AckT: 4 WirelessChargerTemplate
 SG_ Ctrl_RdReg_Value : 0|32@1+ (1,0) [0|0] "" Vector__XXX

BO_ 1024 Control_ReadReg: 6 Applications
 SG_ Ctrl_RdReg_DataLen : 8|8@1+ (1,0) [0|0] ""  WirelessCharger_1,WirelessChargerTemplate
 SG_ Ctrl_RdReg_Address : 16|32@1+ (1,0) [0|0] ""  WirelessCharger_1,WirelessChargerTemplate
 SG_ Ctrl_RdReg_Board : 0|8@1+ (1,0) [0|0] ""  WirelessCharger_1,WirelessChargerTemplate

BO_ 1505 ChargerMeasurementsReportB_1: 3 OnBoardCharger_1
 SG_ Charger_InternalVoltage : 0|20@1+ (0.001,0) [0|1048.575] "Volts"  Applications

BO_ 1506 ChargerMeasurementsReportB_2: 3 Vector__XXX
 SG_ Charger_InternalVoltage : 0|20@1+ (0.001,0) [0|1048.575] "Volts"  Applications

BO_ 1507 ChargerMeasurementsReportB_3: 3 Vector__XXX
 SG_ Charger_InternalVoltage : 0|20@1+ (0.001,0) [0|1048.575] "Volts"  Applications

BO_ 1508 ChargerMeasurementsReportB_4: 3 Vector__XXX
 SG_ Charger_InternalVoltage : 0|20@1+ (0.001,0) [0|1048.575] "Volts"  Applications

BO_ 1509 ChargerMeasurementsReportB_5: 3 Vector__XXX
 SG_ Charger_InternalVoltage : 0|20@1+ (0.001,0) [0|1048.575] "Volts"  Applications

BO_ 1510 ChargerMeasurementsReportB_6: 3 Vector__XXX
 SG_ Charger_InternalVoltage : 0|20@1+ (0.001,0) [0|1048.575] "Volts"  Applications

BO_ 1511 ChargerMeasurementsReportB_7: 3 Vector__XXX
 SG_ Charger_InternalVoltage : 0|20@1+ (0.001,0) [0|1048.575] "Volts"  Applications

BO_ 1512 ChargerMeasurementsReportB_8: 3 Vector__XXX
 SG_ Charger_InternalVoltage : 0|20@1+ (0.001,0) [0|1048.575] "Volts"  Applications

BO_ 1513 ChargerMeasurementsReportB_9: 3 Vector__XXX
 SG_ Charger_InternalVoltage : 0|20@1+ (0.001,0) [0|1048.575] "Volts"  Applications

BO_ 1514 ChargerMeasurementsReportB_10: 3 Vector__XXX
 SG_ Charger_InternalVoltage : 0|20@1+ (0.001,0) [0|1048.575] "Volts"  Applications

BO_ 1504 ChargerMeasurementsReportB_T: 3 OnBoardChargerTemplate
 SG_ Charger_InternalVoltage : 0|20@1+ (0.001,0) [0|1048.575] "Volts" Vector__XXX

BO_ 1729 ProfileLoadRequestAck_1: 8 OnBoardCharger_1
 SG_ ProfileAckNackRequest_1 : 0|8@1+ (1,0) [0|0] ""  Applications

BO_ 1730 ProfileLoadRequestAck_2: 8 Vector__XXX
 SG_ ProfileAckNackRequest_2 : 0|8@1+ (1,0) [0|0] ""  Applications

BO_ 1731 ProfileLoadRequestAck_3: 8 Vector__XXX
 SG_ ProfileAckNackRequest_3 : 0|8@1+ (1,0) [0|0] ""  Applications

BO_ 1732 ProfileLoadRequestAck_4: 8 Vector__XXX
 SG_ ProfileAckNackRequest_4 : 0|8@1+ (1,0) [0|0] ""  Applications

BO_ 1733 ProfileLoadRequestAck_5: 8 Vector__XXX
 SG_ ProfileAckNackRequest_5 : 0|8@1+ (1,0) [0|0] ""  Applications

BO_ 1734 ProfileLoadRequestAck_6: 8 Vector__XXX
 SG_ ProfileAckNackRequest_6 : 0|8@1+ (1,0) [0|0] ""  Applications

BO_ 1735 ProfileLoadRequestAck_7: 8 Vector__XXX
 SG_ ProfileAckNackRequest_7 : 0|8@1+ (1,0) [0|0] ""  Applications

BO_ 1736 ProfileLoadRequestAck_8: 8 Vector__XXX
 SG_ ProfileAckNackRequest_8 : 0|8@1+ (1,0) [0|0] ""  Applications

BO_ 1737 ProfileLoadRequestAck_9: 8 Vector__XXX
 SG_ ProfileAckNackRequest_9 : 0|8@1+ (1,0) [0|0] ""  Applications

BO_ 1738 ProfileLoadRequestAck_10: 8 Vector__XXX
 SG_ ProfileAckNackRequest_10 : 0|8@1+ (1,0) [0|0] ""  Applications

BO_ 1745 ProfileLoadDataAck_1: 8 OnBoardCharger_1
 SG_ ProfileMessageSequence_1 : 8|5@1+ (1,0) [0|31] ""  Applications
 SG_ ProfileAckNackData_1 : 0|8@1+ (1,0) [0|0] ""  Applications

BO_ 1746 ProfileLoadDataAck_2: 8 Vector__XXX
 SG_ ProfileMessageSequence_2 : 8|5@1+ (1,0) [0|31] ""  Applications
 SG_ ProfileAckNackData_2 : 0|8@1+ (1,0) [0|0] ""  Applications

BO_ 1747 ProfileLoadDataAck_3: 8 Vector__XXX
 SG_ ProfileMessageSequence_3 : 8|5@1+ (1,0) [0|31] ""  Applications
 SG_ ProfileAckNackData_3 : 0|8@1+ (1,0) [0|0] ""  Applications

BO_ 1748 ProfileLoadDataAck_4: 8 Vector__XXX
 SG_ ProfileMessageSequence_4 : 8|5@1+ (1,0) [0|31] ""  Applications
 SG_ ProfileAckNackData_4 : 0|8@1+ (1,0) [0|0] ""  Applications

BO_ 1749 ProfileLoadDataAck_5: 8 Vector__XXX
 SG_ ProfileMessageSequence_5 : 8|5@1+ (1,0) [0|31] ""  Applications
 SG_ ProfileAckNackData_5 : 0|8@1+ (1,0) [0|0] ""  Applications

BO_ 1750 ProfileLoadDataAck_6: 8 Vector__XXX
 SG_ ProfileMessageSequence_6 : 8|5@1+ (1,0) [0|31] ""  Applications
 SG_ ProfileAckNackData_6 : 0|8@1+ (1,0) [0|0] ""  Applications

BO_ 1751 ProfileLoadDataAck_7: 8 Vector__XXX
 SG_ ProfileMessageSequence_7 : 8|5@1+ (1,0) [0|31] ""  Applications
 SG_ ProfileAckNackData_7 : 0|8@1+ (1,0) [0|0] ""  Applications

BO_ 1752 ProfileLoadDataAck_8: 8 Vector__XXX
 SG_ ProfileMessageSequence_8 : 8|5@1+ (1,0) [0|31] ""  Applications
 SG_ ProfileAckNackData_8 : 0|8@1+ (1,0) [0|0] ""  Applications

BO_ 1753 ProfileLoadDataAck_9: 8 Vector__XXX
 SG_ ProfileMessageSequence_9 : 8|5@1+ (1,0) [0|31] ""  Applications
 SG_ ProfileAckNackData_9 : 0|8@1+ (1,0) [0|0] ""  Applications

BO_ 1754 ProfileLoadDataAck_10: 8 Vector__XXX
 SG_ ProfileMessageSequence_10 : 8|5@1+ (1,0) [0|31] ""  Applications
 SG_ ProfileAckNackData_10 : 0|8@1+ (1,0) [0|0] ""  Applications

BO_ 1761 ProfileLoadCompleteAck_1: 8 OnBoardCharger_1
 SG_ ProfileAckNackComplete_1 : 0|8@1+ (1,0) [0|0] ""  Applications

BO_ 1762 ProfileLoadCompleteAck_2: 8 Vector__XXX
 SG_ ProfileAckNackComplete_2 : 0|8@1+ (1,0) [0|0] ""  Applications

BO_ 1763 ProfileLoadCompleteAck_3: 8 Vector__XXX
 SG_ ProfileAckNackComplete_3 : 0|8@1+ (1,0) [0|0] ""  Applications

BO_ 1764 ProfileLoadCompleteAck_4: 8 Vector__XXX
 SG_ ProfileAckNackComplete_4 : 0|8@1+ (1,0) [0|0] ""  Applications

BO_ 1765 ProfileLoadCompleteAck_5: 8 Vector__XXX
 SG_ ProfileAckNackComplete_5 : 0|8@1+ (1,0) [0|0] ""  Applications

BO_ 1766 ProfileLoadCompleteAck_6: 8 Vector__XXX
 SG_ ProfileAckNackComplete_6 : 0|8@1+ (1,0) [0|0] ""  Applications

BO_ 1767 ProfileLoadCompleteAck_7: 8 Vector__XXX
 SG_ ProfileAckNackComplete_7 : 0|8@1+ (1,0) [0|0] ""  Applications

BO_ 1768 ProfileLoadCompleteAck_8: 8 Vector__XXX
 SG_ ProfileAckNackComplete_8 : 0|8@1+ (1,0) [0|0] ""  Applications

BO_ 1769 ProfileLoadCompleteAck_9: 8 Vector__XXX
 SG_ ProfileAckNackComplete_9 : 0|8@1+ (1,0) [0|0] ""  Applications

BO_ 1770 ProfileLoadCompleteAck_10: 8 Vector__XXX
 SG_ ProfileAckNackComplete_10 : 0|8@1+ (1,0) [0|0] ""  Applications

BO_ 1873 ConfigurationReportD_1: 1 OnBoardCharger_1
 SG_ Config_SelectedProfile : 0|8@1+ (1,0) [0|0] ""  Applications

BO_ 1874 ConfigurationReportD_2: 1 Vector__XXX
 SG_ Config_SelectedProfile : 0|8@1+ (1,0) [0|0] ""  Applications

BO_ 1875 ConfigurationReportD_3: 1 Vector__XXX
 SG_ Config_SelectedProfile : 0|8@1+ (1,0) [0|0] ""  Applications

BO_ 1876 ConfigurationReportD_4: 1 Vector__XXX
 SG_ Config_SelectedProfile : 0|8@1+ (1,0) [0|0] ""  Applications

BO_ 1877 ConfigurationReportD_5: 1 Vector__XXX
 SG_ Config_SelectedProfile : 0|8@1+ (1,0) [0|0] ""  Applications

BO_ 1878 ConfigurationReportD_6: 1 Vector__XXX
 SG_ Config_SelectedProfile : 0|8@1+ (1,0) [0|0] ""  Applications

BO_ 1879 ConfigurationReportD_7: 1 Vector__XXX
 SG_ Config_SelectedProfile : 0|8@1+ (1,0) [0|0] ""  Applications

BO_ 1880 ConfigurationReportD_8: 1 Vector__XXX
 SG_ Config_SelectedProfile : 0|8@1+ (1,0) [0|0] ""  Applications

BO_ 1881 ConfigurationReportD_9: 1 Vector__XXX
 SG_ Config_SelectedProfile : 0|8@1+ (1,0) [0|0] ""  Applications

BO_ 1882 ConfigurationReportD_10: 1 Vector__XXX
 SG_ Config_SelectedProfile : 0|8@1+ (1,0) [0|0] ""  Applications

BO_ 1857 ConfigurationReportC_1: 2 OnBoardCharger_1
 SG_ Report_CableResistance : 0|16@1+ (0.1,0) [0|6553.5] "mOhm"  Applications

BO_ 1858 ConfigurationReportC_2: 2 Vector__XXX
 SG_ Report_CableResistance : 0|16@1+ (0.1,0) [0|6553.5] "mOhm"  Applications

BO_ 1859 ConfigurationReportC_3: 2 Vector__XXX
 SG_ Report_CableResistance : 0|16@1+ (0.1,0) [0|6553.5] "mOhm"  Applications

BO_ 1860 ConfigurationReportC_4: 2 Vector__XXX
 SG_ Report_CableResistance : 0|16@1+ (0.1,0) [0|6553.5] "mOhm"  Applications

BO_ 1861 ConfigurationReportC_5: 2 Vector__XXX
 SG_ Report_CableResistance : 0|16@1+ (0.1,0) [0|6553.5] "mOhm"  Applications

BO_ 1862 ConfigurationReportC_6: 2 Vector__XXX
 SG_ Report_CableResistance : 0|16@1+ (0.1,0) [0|6553.5] "mOhm"  Applications

BO_ 1863 ConfigurationReportC_7: 2 Vector__XXX
 SG_ Report_CableResistance : 0|16@1+ (0.1,0) [0|6553.5] "mOhm"  Applications

BO_ 1864 ConfigurationReportC_8: 2 Vector__XXX
 SG_ Report_CableResistance : 0|16@1+ (0.1,0) [0|6553.5] "mOhm"  Applications

BO_ 1865 ConfigurationReportC_9: 2 Vector__XXX
 SG_ Report_CableResistance : 0|16@1+ (0.1,0) [0|6553.5] "mOhm"  Applications

BO_ 1866 ConfigurationReportC_10: 2 Vector__XXX
 SG_ Report_CableResistance : 0|16@1+ (0.1,0) [0|6553.5] "mOhm"  Applications

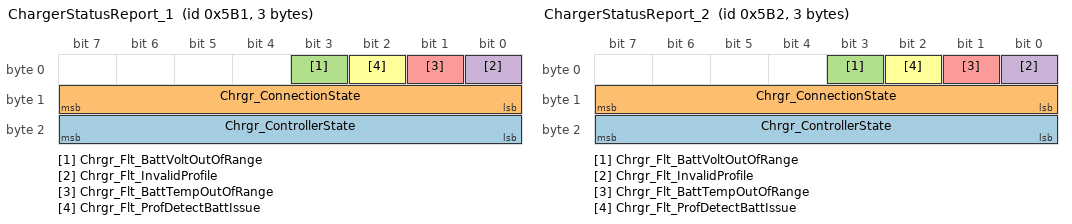
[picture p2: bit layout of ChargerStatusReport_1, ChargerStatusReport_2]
BO_ 1457 ChargerStatusReport_1: 3 OnBoardCharger_1
 SG_ Chrgr_ControllerState : 16|8@1+ (1,0) [0|0] ""  Applications
 SG_ Chrgr_ConnectionState : 8|8@1+ (1,0) [0|0] ""  Applications
 SG_ Chrgr_Flt_BattVoltOutOfRange : 3|1@1+ (1,0) [0|1] ""  Applications
 SG_ Chrgr_Flt_InvalidProfile : 0|1@1+ (1,0) [0|1] ""  Applications
 SG_ Chrgr_Flt_BattTempOutOfRange : 1|1@1+ (1,0) [0|1] ""  Applications
 SG_ Chrgr_Flt_ProfDetectBattIssue : 2|1@1+ (1,0) [0|1] ""  Applications

BO_ 1458 ChargerStatusReport_2: 3 Vector__XXX
 SG_ Chrgr_ControllerState : 16|8@1+ (1,0) [0|0] ""  Applications
 SG_ Chrgr_ConnectionState : 8|8@1+ (1,0) [0|0] ""  Applications
 SG_ Chrgr_Flt_BattVoltOutOfRange : 3|1@1+ (1,0) [0|1] ""  Applications
 SG_ Chrgr_Flt_InvalidProfile : 0|1@1+ (1,0) [0|1] ""  Applications
 SG_ Chrgr_Flt_BattTempOutOfRange : 1|1@1+ (1,0) [0|1] ""  Applications
 SG_ Chrgr_Flt_ProfDetectBattIssue : 2|1@1+ (1,0) [0|1] ""  Applications

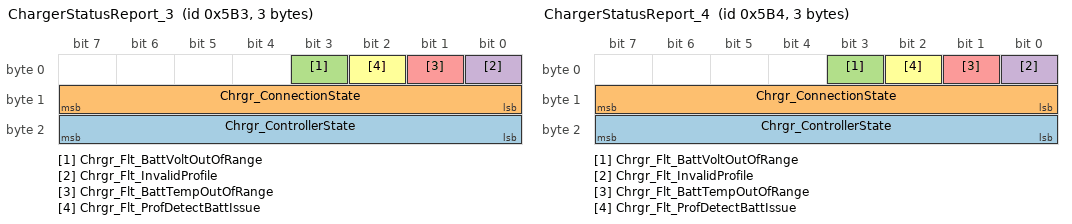
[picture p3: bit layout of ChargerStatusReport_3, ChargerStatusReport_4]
BO_ 1459 ChargerStatusReport_3: 3 Vector__XXX
 SG_ Chrgr_ControllerState : 16|8@1+ (1,0) [0|0] ""  Applications
 SG_ Chrgr_ConnectionState : 8|8@1+ (1,0) [0|0] ""  Applications
 SG_ Chrgr_Flt_BattVoltOutOfRange : 3|1@1+ (1,0) [0|1] ""  Applications
 SG_ Chrgr_Flt_InvalidProfile : 0|1@1+ (1,0) [0|1] ""  Applications
 SG_ Chrgr_Flt_BattTempOutOfRange : 1|1@1+ (1,0) [0|1] ""  Applications
 SG_ Chrgr_Flt_ProfDetectBattIssue : 2|1@1+ (1,0) [0|1] ""  Applications

BO_ 1460 ChargerStatusReport_4: 3 Vector__XXX
 SG_ Chrgr_ControllerState : 16|8@1+ (1,0) [0|0] ""  Applications
 SG_ Chrgr_ConnectionState : 8|8@1+ (1,0) [0|0] ""  Applications
 SG_ Chrgr_Flt_BattVoltOutOfRange : 3|1@1+ (1,0) [0|1] ""  Applications
 SG_ Chrgr_Flt_InvalidProfile : 0|1@1+ (1,0) [0|1] ""  Applications
 SG_ Chrgr_Flt_BattTempOutOfRange : 1|1@1+ (1,0) [0|1] ""  Applications
 SG_ Chrgr_Flt_ProfDetectBattIssue : 2|1@1+ (1,0) [0|1] ""  Applications

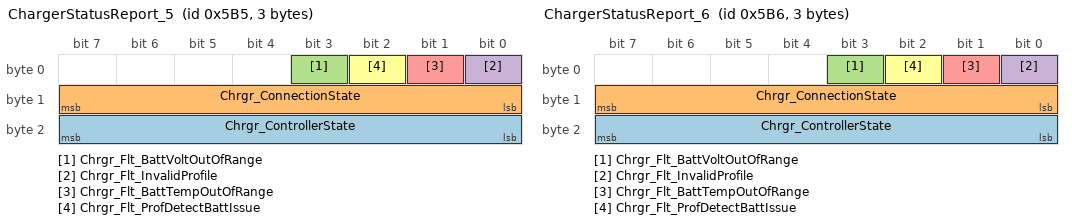
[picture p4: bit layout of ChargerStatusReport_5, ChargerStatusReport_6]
BO_ 1461 ChargerStatusReport_5: 3 Vector__XXX
 SG_ Chrgr_ControllerState : 16|8@1+ (1,0) [0|0] ""  Applications
 SG_ Chrgr_ConnectionState : 8|8@1+ (1,0) [0|0] ""  Applications
 SG_ Chrgr_Flt_BattVoltOutOfRange : 3|1@1+ (1,0) [0|1] ""  Applications
 SG_ Chrgr_Flt_InvalidProfile : 0|1@1+ (1,0) [0|1] ""  Applications
 SG_ Chrgr_Flt_BattTempOutOfRange : 1|1@1+ (1,0) [0|1] ""  Applications
 SG_ Chrgr_Flt_ProfDetectBattIssue : 2|1@1+ (1,0) [0|1] ""  Applications

BO_ 1462 ChargerStatusReport_6: 3 Vector__XXX
 SG_ Chrgr_ControllerState : 16|8@1+ (1,0) [0|0] ""  Applications
 SG_ Chrgr_ConnectionState : 8|8@1+ (1,0) [0|0] ""  Applications
 SG_ Chrgr_Flt_BattVoltOutOfRange : 3|1@1+ (1,0) [0|1] ""  Applications
 SG_ Chrgr_Flt_InvalidProfile : 0|1@1+ (1,0) [0|1] ""  Applications
 SG_ Chrgr_Flt_BattTempOutOfRange : 1|1@1+ (1,0) [0|1] ""  Applications
 SG_ Chrgr_Flt_ProfDetectBattIssue : 2|1@1+ (1,0) [0|1] ""  Applications

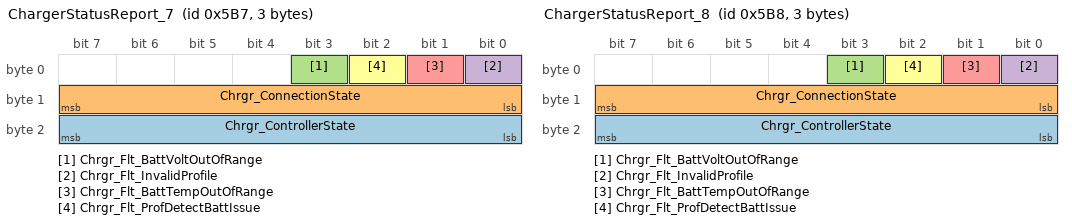
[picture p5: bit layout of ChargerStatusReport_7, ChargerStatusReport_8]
BO_ 1463 ChargerStatusReport_7: 3 Vector__XXX
 SG_ Chrgr_ControllerState : 16|8@1+ (1,0) [0|0] ""  Applications
 SG_ Chrgr_ConnectionState : 8|8@1+ (1,0) [0|0] ""  Applications
 SG_ Chrgr_Flt_BattVoltOutOfRange : 3|1@1+ (1,0) [0|1] ""  Applications
 SG_ Chrgr_Flt_InvalidProfile : 0|1@1+ (1,0) [0|1] ""  Applications
 SG_ Chrgr_Flt_BattTempOutOfRange : 1|1@1+ (1,0) [0|1] ""  Applications
 SG_ Chrgr_Flt_ProfDetectBattIssue : 2|1@1+ (1,0) [0|1] ""  Applications

BO_ 1464 ChargerStatusReport_8: 3 Vector__XXX
 SG_ Chrgr_ControllerState : 16|8@1+ (1,0) [0|0] ""  Applications
 SG_ Chrgr_ConnectionState : 8|8@1+ (1,0) [0|0] ""  Applications
 SG_ Chrgr_Flt_BattVoltOutOfRange : 3|1@1+ (1,0) [0|1] ""  Applications
 SG_ Chrgr_Flt_InvalidProfile : 0|1@1+ (1,0) [0|1] ""  Applications
 SG_ Chrgr_Flt_BattTempOutOfRange : 1|1@1+ (1,0) [0|1] ""  Applications
 SG_ Chrgr_Flt_ProfDetectBattIssue : 2|1@1+ (1,0) [0|1] ""  Applications

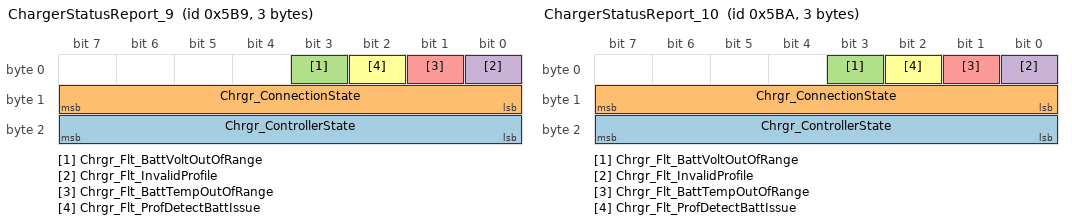
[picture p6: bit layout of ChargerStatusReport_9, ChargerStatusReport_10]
BO_ 1465 ChargerStatusReport_9: 3 Vector__XXX
 SG_ Chrgr_ControllerState : 16|8@1+ (1,0) [0|0] ""  Applications
 SG_ Chrgr_ConnectionState : 8|8@1+ (1,0) [0|0] ""  Applications
 SG_ Chrgr_Flt_BattVoltOutOfRange : 3|1@1+ (1,0) [0|1] ""  Applications
 SG_ Chrgr_Flt_InvalidProfile : 0|1@1+ (1,0) [0|1] ""  Applications
 SG_ Chrgr_Flt_BattTempOutOfRange : 1|1@1+ (1,0) [0|1] ""  Applications
 SG_ Chrgr_Flt_ProfDetectBattIssue : 2|1@1+ (1,0) [0|1] ""  Applications

BO_ 1466 ChargerStatusReport_10: 3 Vector__XXX
 SG_ Chrgr_ControllerState : 16|8@1+ (1,0) [0|0] ""  Applications
 SG_ Chrgr_ConnectionState : 8|8@1+ (1,0) [0|0] ""  Applications
 SG_ Chrgr_Flt_BattVoltOutOfRange : 3|1@1+ (1,0) [0|1] ""  Applications
 SG_ Chrgr_Flt_InvalidProfile : 0|1@1+ (1,0) [0|1] ""  Applications
 SG_ Chrgr_Flt_BattTempOutOfRange : 1|1@1+ (1,0) [0|1] ""  Applications
 SG_ Chrgr_Flt_ProfDetectBattIssue : 2|1@1+ (1,0) [0|1] ""  Applications

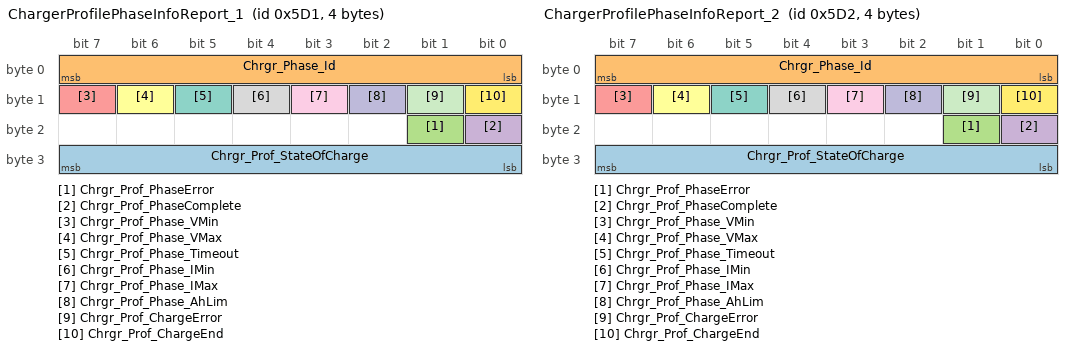
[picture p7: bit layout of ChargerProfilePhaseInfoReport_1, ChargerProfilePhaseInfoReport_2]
BO_ 1489 ChargerProfilePhaseInfoReport_1: 4 OnBoardCharger_1
 SG_ Chrgr_Prof_StateOfCharge : 24|8@1+ (1,0) [0|100] ""  Applications
 SG_ Chrgr_Phase_Id : 0|8@1- (1,0) [-128|127] ""  Applications
 SG_ Chrgr_Prof_PhaseError : 17|1@1+ (1,0) [0|1] ""  Applications
 SG_ Chrgr_Prof_PhaseComplete : 16|1@1+ (1,0) [0|1] ""  Applications
 SG_ Chrgr_Prof_Phase_VMin : 15|1@1+ (1,0) [0|1] ""  Applications
 SG_ Chrgr_Prof_Phase_VMax : 14|1@1+ (1,0) [0|1] ""  Applications
 SG_ Chrgr_Prof_Phase_Timeout : 13|1@1+ (1,0) [0|1] ""  Applications
 SG_ Chrgr_Prof_Phase_IMin : 12|1@1+ (1,0) [0|1] ""  Applications
 SG_ Chrgr_Prof_Phase_IMax : 11|1@1+ (1,0) [0|1] ""  Applications
 SG_ Chrgr_Prof_Phase_AhLim : 10|1@1+ (1,0) [0|1] ""  Applications
 SG_ Chrgr_Prof_ChargeError : 9|1@1+ (1,0) [0|1] ""  Applications
 SG_ Chrgr_Prof_ChargeEnd : 8|1@1+ (1,0) [0|1] ""  Applications

BO_ 1490 ChargerProfilePhaseInfoReport_2: 4 Vector__XXX
 SG_ Chrgr_Prof_StateOfCharge : 24|8@1+ (1,0) [0|100] ""  Applications
 SG_ Chrgr_Phase_Id : 0|8@1- (1,0) [-128|127] ""  Applications
 SG_ Chrgr_Prof_PhaseError : 17|1@1+ (1,0) [0|1] ""  Applications
 SG_ Chrgr_Prof_PhaseComplete : 16|1@1+ (1,0) [0|1] ""  Applications
 SG_ Chrgr_Prof_Phase_VMin : 15|1@1+ (1,0) [0|1] ""  Applications
 SG_ Chrgr_Prof_Phase_VMax : 14|1@1+ (1,0) [0|1] ""  Applications
 SG_ Chrgr_Prof_Phase_Timeout : 13|1@1+ (1,0) [0|1] ""  Applications
 SG_ Chrgr_Prof_Phase_IMin : 12|1@1+ (1,0) [0|1] ""  Applications
 SG_ Chrgr_Prof_Phase_IMax : 11|1@1+ (1,0) [0|1] ""  Applications
 SG_ Chrgr_Prof_Phase_AhLim : 10|1@1+ (1,0) [0|1] ""  Applications
 SG_ Chrgr_Prof_ChargeError : 9|1@1+ (1,0) [0|1] ""  Applications
 SG_ Chrgr_Prof_ChargeEnd : 8|1@1+ (1,0) [0|1] ""  Applications

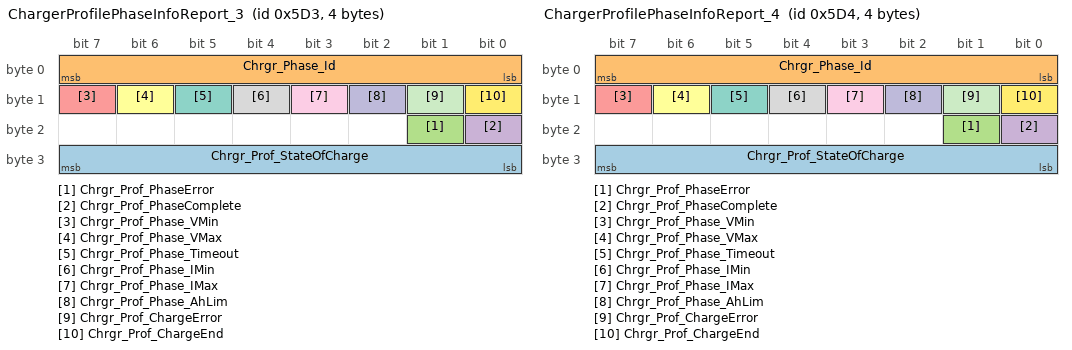
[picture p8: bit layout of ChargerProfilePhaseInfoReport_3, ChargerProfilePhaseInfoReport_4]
BO_ 1491 ChargerProfilePhaseInfoReport_3: 4 Vector__XXX
 SG_ Chrgr_Prof_StateOfCharge : 24|8@1+ (1,0) [0|100] ""  Applications
 SG_ Chrgr_Phase_Id : 0|8@1- (1,0) [-128|127] ""  Applications
 SG_ Chrgr_Prof_PhaseError : 17|1@1+ (1,0) [0|1] ""  Applications
 SG_ Chrgr_Prof_PhaseComplete : 16|1@1+ (1,0) [0|1] ""  Applications
 SG_ Chrgr_Prof_Phase_VMin : 15|1@1+ (1,0) [0|1] ""  Applications
 SG_ Chrgr_Prof_Phase_VMax : 14|1@1+ (1,0) [0|1] ""  Applications
 SG_ Chrgr_Prof_Phase_Timeout : 13|1@1+ (1,0) [0|1] ""  Applications
 SG_ Chrgr_Prof_Phase_IMin : 12|1@1+ (1,0) [0|1] ""  Applications
 SG_ Chrgr_Prof_Phase_IMax : 11|1@1+ (1,0) [0|1] ""  Applications
 SG_ Chrgr_Prof_Phase_AhLim : 10|1@1+ (1,0) [0|1] ""  Applications
 SG_ Chrgr_Prof_ChargeError : 9|1@1+ (1,0) [0|1] ""  Applications
 SG_ Chrgr_Prof_ChargeEnd : 8|1@1+ (1,0) [0|1] ""  Applications

BO_ 1492 ChargerProfilePhaseInfoReport_4: 4 Vector__XXX
 SG_ Chrgr_Prof_StateOfCharge : 24|8@1+ (1,0) [0|100] ""  Applications
 SG_ Chrgr_Phase_Id : 0|8@1- (1,0) [-128|127] ""  Applications
 SG_ Chrgr_Prof_PhaseError : 17|1@1+ (1,0) [0|1] ""  Applications
 SG_ Chrgr_Prof_PhaseComplete : 16|1@1+ (1,0) [0|1] ""  Applications
 SG_ Chrgr_Prof_Phase_VMin : 15|1@1+ (1,0) [0|1] ""  Applications
 SG_ Chrgr_Prof_Phase_VMax : 14|1@1+ (1,0) [0|1] ""  Applications
 SG_ Chrgr_Prof_Phase_Timeout : 13|1@1+ (1,0) [0|1] ""  Applications
 SG_ Chrgr_Prof_Phase_IMin : 12|1@1+ (1,0) [0|1] ""  Applications
 SG_ Chrgr_Prof_Phase_IMax : 11|1@1+ (1,0) [0|1] ""  Applications
 SG_ Chrgr_Prof_Phase_AhLim : 10|1@1+ (1,0) [0|1] ""  Applications
 SG_ Chrgr_Prof_ChargeError : 9|1@1+ (1,0) [0|1] ""  Applications
 SG_ Chrgr_Prof_ChargeEnd : 8|1@1+ (1,0) [0|1] ""  Applications

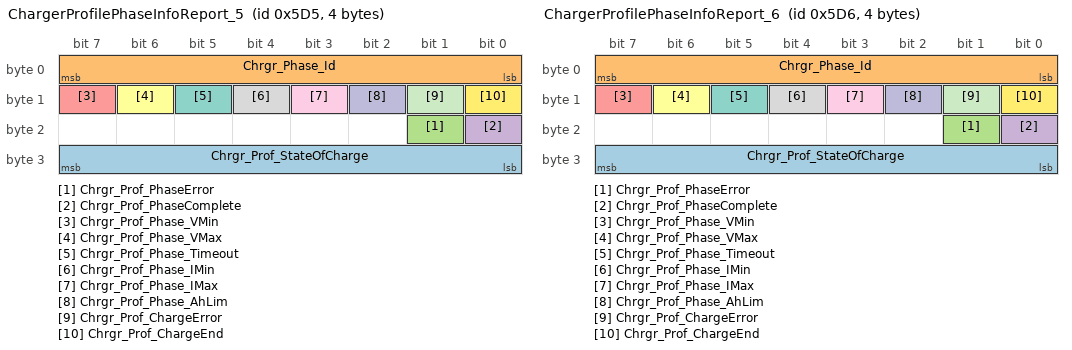
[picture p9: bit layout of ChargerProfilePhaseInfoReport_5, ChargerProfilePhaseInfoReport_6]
BO_ 1493 ChargerProfilePhaseInfoReport_5: 4 Vector__XXX
 SG_ Chrgr_Prof_StateOfCharge : 24|8@1+ (1,0) [0|100] ""  Applications
 SG_ Chrgr_Phase_Id : 0|8@1- (1,0) [-128|127] ""  Applications
 SG_ Chrgr_Prof_PhaseError : 17|1@1+ (1,0) [0|1] ""  Applications
 SG_ Chrgr_Prof_PhaseComplete : 16|1@1+ (1,0) [0|1] ""  Applications
 SG_ Chrgr_Prof_Phase_VMin : 15|1@1+ (1,0) [0|1] ""  Applications
 SG_ Chrgr_Prof_Phase_VMax : 14|1@1+ (1,0) [0|1] ""  Applications
 SG_ Chrgr_Prof_Phase_Timeout : 13|1@1+ (1,0) [0|1] ""  Applications
 SG_ Chrgr_Prof_Phase_IMin : 12|1@1+ (1,0) [0|1] ""  Applications
 SG_ Chrgr_Prof_Phase_IMax : 11|1@1+ (1,0) [0|1] ""  Applications
 SG_ Chrgr_Prof_Phase_AhLim : 10|1@1+ (1,0) [0|1] ""  Applications
 SG_ Chrgr_Prof_ChargeError : 9|1@1+ (1,0) [0|1] ""  Applications
 SG_ Chrgr_Prof_ChargeEnd : 8|1@1+ (1,0) [0|1] ""  Applications

BO_ 1494 ChargerProfilePhaseInfoReport_6: 4 Vector__XXX
 SG_ Chrgr_Prof_StateOfCharge : 24|8@1+ (1,0) [0|100] ""  Applications
 SG_ Chrgr_Phase_Id : 0|8@1- (1,0) [-128|127] ""  Applications
 SG_ Chrgr_Prof_PhaseError : 17|1@1+ (1,0) [0|1] ""  Applications
 SG_ Chrgr_Prof_PhaseComplete : 16|1@1+ (1,0) [0|1] ""  Applications
 SG_ Chrgr_Prof_Phase_VMin : 15|1@1+ (1,0) [0|1] ""  Applications
 SG_ Chrgr_Prof_Phase_VMax : 14|1@1+ (1,0) [0|1] ""  Applications
 SG_ Chrgr_Prof_Phase_Timeout : 13|1@1+ (1,0) [0|1] ""  Applications
 SG_ Chrgr_Prof_Phase_IMin : 12|1@1+ (1,0) [0|1] ""  Applications
 SG_ Chrgr_Prof_Phase_IMax : 11|1@1+ (1,0) [0|1] ""  Applications
 SG_ Chrgr_Prof_Phase_AhLim : 10|1@1+ (1,0) [0|1] ""  Applications
 SG_ Chrgr_Prof_ChargeError : 9|1@1+ (1,0) [0|1] ""  Applications
 SG_ Chrgr_Prof_ChargeEnd : 8|1@1+ (1,0) [0|1] ""  Applications

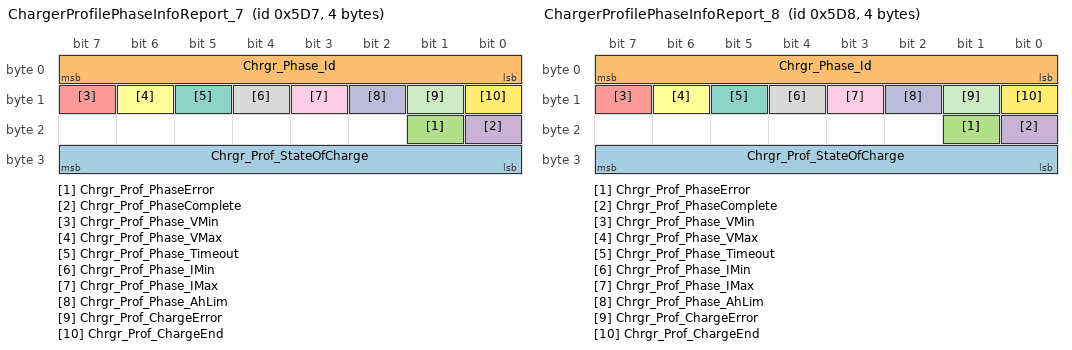
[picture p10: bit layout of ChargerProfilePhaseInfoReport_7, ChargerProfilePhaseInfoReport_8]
BO_ 1495 ChargerProfilePhaseInfoReport_7: 4 Vector__XXX
 SG_ Chrgr_Prof_StateOfCharge : 24|8@1+ (1,0) [0|100] ""  Applications
 SG_ Chrgr_Phase_Id : 0|8@1- (1,0) [-128|127] ""  Applications
 SG_ Chrgr_Prof_PhaseError : 17|1@1+ (1,0) [0|1] ""  Applications
 SG_ Chrgr_Prof_PhaseComplete : 16|1@1+ (1,0) [0|1] ""  Applications
 SG_ Chrgr_Prof_Phase_VMin : 15|1@1+ (1,0) [0|1] ""  Applications
 SG_ Chrgr_Prof_Phase_VMax : 14|1@1+ (1,0) [0|1] ""  Applications
 SG_ Chrgr_Prof_Phase_Timeout : 13|1@1+ (1,0) [0|1] ""  Applications
 SG_ Chrgr_Prof_Phase_IMin : 12|1@1+ (1,0) [0|1] ""  Applications
 SG_ Chrgr_Prof_Phase_IMax : 11|1@1+ (1,0) [0|1] ""  Applications
 SG_ Chrgr_Prof_Phase_AhLim : 10|1@1+ (1,0) [0|1] ""  Applications
 SG_ Chrgr_Prof_ChargeError : 9|1@1+ (1,0) [0|1] ""  Applications
 SG_ Chrgr_Prof_ChargeEnd : 8|1@1+ (1,0) [0|1] ""  Applications

BO_ 1496 ChargerProfilePhaseInfoReport_8: 4 Vector__XXX
 SG_ Chrgr_Prof_StateOfCharge : 24|8@1+ (1,0) [0|100] ""  Applications
 SG_ Chrgr_Phase_Id : 0|8@1- (1,0) [-128|127] ""  Applications
 SG_ Chrgr_Prof_PhaseError : 17|1@1+ (1,0) [0|1] ""  Applications
 SG_ Chrgr_Prof_PhaseComplete : 16|1@1+ (1,0) [0|1] ""  Applications
 SG_ Chrgr_Prof_Phase_VMin : 15|1@1+ (1,0) [0|1] ""  Applications
 SG_ Chrgr_Prof_Phase_VMax : 14|1@1+ (1,0) [0|1] ""  Applications
 SG_ Chrgr_Prof_Phase_Timeout : 13|1@1+ (1,0) [0|1] ""  Applications
 SG_ Chrgr_Prof_Phase_IMin : 12|1@1+ (1,0) [0|1] ""  Applications
 SG_ Chrgr_Prof_Phase_IMax : 11|1@1+ (1,0) [0|1] ""  Applications
 SG_ Chrgr_Prof_Phase_AhLim : 10|1@1+ (1,0) [0|1] ""  Applications
 SG_ Chrgr_Prof_ChargeError : 9|1@1+ (1,0) [0|1] ""  Applications
 SG_ Chrgr_Prof_ChargeEnd : 8|1@1+ (1,0) [0|1] ""  Applications

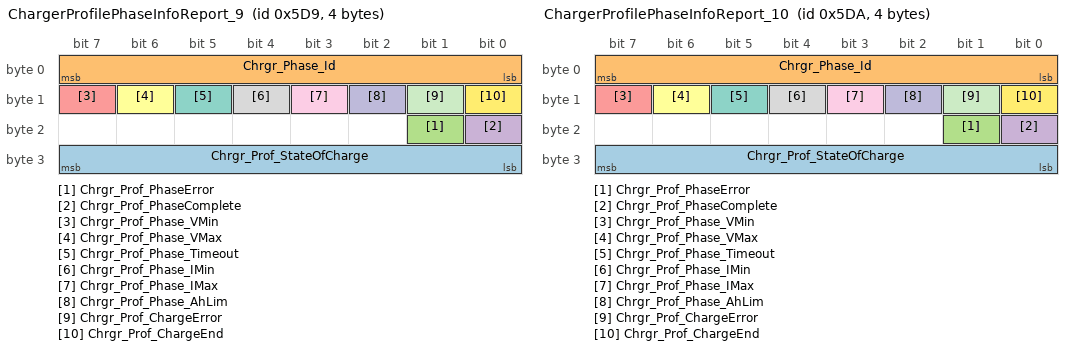
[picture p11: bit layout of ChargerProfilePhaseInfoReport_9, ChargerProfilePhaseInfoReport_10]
BO_ 1497 ChargerProfilePhaseInfoReport_9: 4 Vector__XXX
 SG_ Chrgr_Prof_StateOfCharge : 24|8@1+ (1,0) [0|100] ""  Applications
 SG_ Chrgr_Phase_Id : 0|8@1- (1,0) [-128|127] ""  Applications
 SG_ Chrgr_Prof_PhaseError : 17|1@1+ (1,0) [0|1] ""  Applications
 SG_ Chrgr_Prof_PhaseComplete : 16|1@1+ (1,0) [0|1] ""  Applications
 SG_ Chrgr_Prof_Phase_VMin : 15|1@1+ (1,0) [0|1] ""  Applications
 SG_ Chrgr_Prof_Phase_VMax : 14|1@1+ (1,0) [0|1] ""  Applications
 SG_ Chrgr_Prof_Phase_Timeout : 13|1@1+ (1,0) [0|1] ""  Applications
 SG_ Chrgr_Prof_Phase_IMin : 12|1@1+ (1,0) [0|1] ""  Applications
 SG_ Chrgr_Prof_Phase_IMax : 11|1@1+ (1,0) [0|1] ""  Applications
 SG_ Chrgr_Prof_Phase_AhLim : 10|1@1+ (1,0) [0|1] ""  Applications
 SG_ Chrgr_Prof_ChargeError : 9|1@1+ (1,0) [0|1] ""  Applications
 SG_ Chrgr_Prof_ChargeEnd : 8|1@1+ (1,0) [0|1] ""  Applications

BO_ 1498 ChargerProfilePhaseInfoReport_10: 4 Vector__XXX
 SG_ Chrgr_Prof_StateOfCharge : 24|8@1+ (1,0) [0|100] ""  Applications
 SG_ Chrgr_Phase_Id : 0|8@1- (1,0) [-128|127] ""  Applications
 SG_ Chrgr_Prof_PhaseError : 17|1@1+ (1,0) [0|1] ""  Applications
 SG_ Chrgr_Prof_PhaseComplete : 16|1@1+ (1,0) [0|1] ""  Applications
 SG_ Chrgr_Prof_Phase_VMin : 15|1@1+ (1,0) [0|1] ""  Applications
 SG_ Chrgr_Prof_Phase_VMax : 14|1@1+ (1,0) [0|1] ""  Applications
 SG_ Chrgr_Prof_Phase_Timeout : 13|1@1+ (1,0) [0|1] ""  Applications
 SG_ Chrgr_Prof_Phase_IMin : 12|1@1+ (1,0) [0|1] ""  Applications
 SG_ Chrgr_Prof_Phase_IMax : 11|1@1+ (1,0) [0|1] ""  Applications
 SG_ Chrgr_Prof_Phase_AhLim : 10|1@1+ (1,0) [0|1] ""  Applications
 SG_ Chrgr_Prof_ChargeError : 9|1@1+ (1,0) [0|1] ""  Applications
 SG_ Chrgr_Prof_ChargeEnd : 8|1@1+ (1,0) [0|1] ""  Applications

BO_ 1473 ChargerProfileInfoReport_1: 5 OnBoardCharger_1
 SG_ Chrgr_Prof_SelectorSwitch : 32|4@1+ (1,0) [0|15] ""  Applications
 SG_ Chrgr_Prof_Id : 0|32@1+ (1,0) [0|4294967295] ""  Applications

BO_ 1474 ChargerProfileInfoReport_2: 5 Vector__XXX
 SG_ Chrgr_Prof_SelectorSwitch : 32|4@1+ (1,0) [0|15] ""  Applications
 SG_ Chrgr_Prof_Id : 0|32@1+ (1,0) [0|4294967295] ""  Applications

BO_ 1475 ChargerProfileInfoReport_3: 5 Vector__XXX
 SG_ Chrgr_Prof_SelectorSwitch : 32|4@1+ (1,0) [0|15] ""  Applications
 SG_ Chrgr_Prof_Id : 0|32@1+ (1,0) [0|4294967295] ""  Applications

BO_ 1476 ChargerProfileInfoReport_4: 5 Vector__XXX
 SG_ Chrgr_Prof_SelectorSwitch : 32|4@1+ (1,0) [0|15] ""  Applications
 SG_ Chrgr_Prof_Id : 0|32@1+ (1,0) [0|4294967295] ""  Applications

BO_ 1477 ChargerProfileInfoReport_5: 5 Vector__XXX
 SG_ Chrgr_Prof_SelectorSwitch : 32|4@1+ (1,0) [0|15] ""  Applications
 SG_ Chrgr_Prof_Id : 0|32@1+ (1,0) [0|4294967295] ""  Applications

BO_ 1478 ChargerProfileInfoReport_6: 5 Vector__XXX
 SG_ Chrgr_Prof_SelectorSwitch : 32|4@1+ (1,0) [0|15] ""  Applications
 SG_ Chrgr_Prof_Id : 0|32@1+ (1,0) [0|4294967295] ""  Applications

BO_ 1479 ChargerProfileInfoReport_7: 5 Vector__XXX
 SG_ Chrgr_Prof_SelectorSwitch : 32|4@1+ (1,0) [0|15] ""  Applications
 SG_ Chrgr_Prof_Id : 0|32@1+ (1,0) [0|4294967295] ""  Applications

BO_ 1480 ChargerProfileInfoReport_8: 5 Vector__XXX
 SG_ Chrgr_Prof_SelectorSwitch : 32|4@1+ (1,0) [0|15] ""  Applications
 SG_ Chrgr_Prof_Id : 0|32@1+ (1,0) [0|4294967295] ""  Applications

BO_ 1481 ChargerProfileInfoReport_9: 5 Vector__XXX
 SG_ Chrgr_Prof_SelectorSwitch : 32|4@1+ (1,0) [0|15] ""  Applications
 SG_ Chrgr_Prof_Id : 0|32@1+ (1,0) [0|4294967295] ""  Applications

BO_ 1482 ChargerProfileInfoReport_10: 5 Vector__XXX
 SG_ Chrgr_Prof_SelectorSwitch : 32|4@1+ (1,0) [0|15] ""  Applications
 SG_ Chrgr_Prof_Id : 0|32@1+ (1,0) [0|4294967295] ""  Applications

BO_ 1441 ChargerMeasurementsReport_1: 8 OnBoardCharger_1
 SG_ Charger_CalculatedBatteryVoltage : 32|32@1+ (0.0009765625,0) [0|4194303.99902344] "V"  Applications
 SG_ ChargerBatteryTemperature : 16|16@1- (0.005,0) [-163.84|163.835] "C"  Applications
 SG_ ChargerTemperature : 0|16@1- (0.005,0) [-163.84|163.835] "C"  Applications

BO_ 1442 ChargerMeasurementsReport_2: 8 Vector__XXX
 SG_ Charger_CalculatedBatteryVoltage : 32|32@1+ (0.0009765625,0) [0|4194303.99902344] "V"  Applications
 SG_ ChargerBatteryTemperature : 16|16@1- (0.005,0) [-163.84|163.835] "C"  Applications
 SG_ ChargerTemperature : 0|16@1- (0.005,0) [-163.84|163.835] "C"  Applications

BO_ 1443 ChargerMeasurementsReport_3: 8 Vector__XXX
 SG_ Charger_CalculatedBatteryVoltage : 32|32@1+ (0.0009765625,0) [0|4194303.99902344] "V"  Applications
 SG_ ChargerBatteryTemperature : 16|16@1- (0.005,0) [-163.84|163.835] "C"  Applications
 SG_ ChargerTemperature : 0|16@1- (0.005,0) [-163.84|163.835] "C"  Applications

BO_ 1444 ChargerMeasurementsReport_4: 8 Vector__XXX
 SG_ Charger_CalculatedBatteryVoltage : 32|32@1+ (0.0009765625,0) [0|4194303.99902344] "V"  Applications
 SG_ ChargerBatteryTemperature : 16|16@1- (0.005,0) [-163.84|163.835] "C"  Applications
 SG_ ChargerTemperature : 0|16@1- (0.005,0) [-163.84|163.835] "C"  Applications

BO_ 1445 ChargerMeasurementsReport_5: 8 Vector__XXX
 SG_ Charger_CalculatedBatteryVoltage : 32|32@1+ (0.0009765625,0) [0|4194303.99902344] "V"  Applications
 SG_ ChargerBatteryTemperature : 16|16@1- (0.005,0) [-163.84|163.835] "C"  Applications
 SG_ ChargerTemperature : 0|16@1- (0.005,0) [-163.84|163.835] "C"  Applications

BO_ 1446 ChargerMeasurementsReport_6: 8 Vector__XXX
 SG_ Charger_CalculatedBatteryVoltage : 32|32@1+ (0.0009765625,0) [0|4194303.99902344] "V"  Applications
 SG_ ChargerBatteryTemperature : 16|16@1- (0.005,0) [-163.84|163.835] "C"  Applications
 SG_ ChargerTemperature : 0|16@1- (0.005,0) [-163.84|163.835] "C"  Applications

BO_ 1447 ChargerMeasurementsReport_7: 8 Vector__XXX
 SG_ Charger_CalculatedBatteryVoltage : 32|32@1+ (0.0009765625,0) [0|4194303.99902344] "V"  Applications
 SG_ ChargerBatteryTemperature : 16|16@1- (0.005,0) [-163.84|163.835] "C"  Applications
 SG_ ChargerTemperature : 0|16@1- (0.005,0) [-163.84|163.835] "C"  Applications

BO_ 1448 ChargerMeasurementsReport_8: 8 Vector__XXX
 SG_ Charger_CalculatedBatteryVoltage : 32|32@1+ (0.0009765625,0) [0|4194303.99902344] "V"  Applications
 SG_ ChargerBatteryTemperature : 16|16@1- (0.005,0) [-163.84|163.835] "C"  Applications
 SG_ ChargerTemperature : 0|16@1- (0.005,0) [-163.84|163.835] "C"  Applications

BO_ 1449 ChargerMeasurementsReport_9: 8 Vector__XXX
 SG_ Charger_CalculatedBatteryVoltage : 32|32@1+ (0.0009765625,0) [0|4194303.99902344] "V"  Applications
 SG_ ChargerBatteryTemperature : 16|16@1- (0.005,0) [-163.84|163.835] "C"  Applications
 SG_ ChargerTemperature : 0|16@1- (0.005,0) [-163.84|163.835] "C"  Applications

BO_ 1450 ChargerMeasurementsReport_10: 8 Vector__XXX
 SG_ Charger_CalculatedBatteryVoltage : 32|32@1+ (0.0009765625,0) [0|4194303.99902344] "V"  Applications
 SG_ ChargerBatteryTemperature : 16|16@1- (0.005,0) [-163.84|163.835] "C"  Applications
 SG_ ChargerTemperature : 0|16@1- (0.005,0) [-163.84|163.835] "C"  Applications

BO_ 977 ModuleLogReportF_1: 3 OnBoardCharger_1
 SG_ Monitor_NumberOfRefreshes : 8|8@1+ (1,0) [0|255] ""  Applications
 SG_ Monitor_EndReason : 0|8@1+ (1,0) [0|255] ""  Applications
 SG_ Monitor_FlagEqualisation : 16|1@1+ (1,0) [0|1] ""  Applications

BO_ 978 ModuleLogReportF_2: 3 Vector__XXX
 SG_ Monitor_NumberOfRefreshes : 8|8@1+ (1,0) [0|255] ""  Applications
 SG_ Monitor_EndReason : 0|8@1+ (1,0) [0|255] ""  Applications
 SG_ Monitor_FlagEqualisation : 16|1@1+ (1,0) [0|1] ""  Applications

BO_ 979 ModuleLogReportF_3: 3 Vector__XXX
 SG_ Monitor_NumberOfRefreshes : 8|8@1+ (1,0) [0|255] ""  Applications
 SG_ Monitor_EndReason : 0|8@1+ (1,0) [0|255] ""  Applications
 SG_ Monitor_FlagEqualisation : 16|1@1+ (1,0) [0|1] ""  Applications

BO_ 980 ModuleLogReportF_4: 3 Vector__XXX
 SG_ Monitor_NumberOfRefreshes : 8|8@1+ (1,0) [0|255] ""  Applications
 SG_ Monitor_EndReason : 0|8@1+ (1,0) [0|255] ""  Applications
 SG_ Monitor_FlagEqualisation : 16|1@1+ (1,0) [0|1] ""  Applications

BO_ 981 ModuleLogReportF_5: 3 Vector__XXX
 SG_ Monitor_NumberOfRefreshes : 8|8@1+ (1,0) [0|255] ""  Applications
 SG_ Monitor_EndReason : 0|8@1+ (1,0) [0|255] ""  Applications
 SG_ Monitor_FlagEqualisation : 16|1@1+ (1,0) [0|1] ""  Applications

BO_ 982 ModuleLogReportF_6: 3 Vector__XXX
 SG_ Monitor_NumberOfRefreshes : 8|8@1+ (1,0) [0|255] ""  Applications
 SG_ Monitor_EndReason : 0|8@1+ (1,0) [0|255] ""  Applications
 SG_ Monitor_FlagEqualisation : 16|1@1+ (1,0) [0|1] ""  Applications

BO_ 983 ModuleLogReportF_7: 3 Vector__XXX
 SG_ Monitor_NumberOfRefreshes : 8|8@1+ (1,0) [0|255] ""  Applications
 SG_ Monitor_EndReason : 0|8@1+ (1,0) [0|255] ""  Applications
 SG_ Monitor_FlagEqualisation : 16|1@1+ (1,0) [0|1] ""  Applications

BO_ 984 ModuleLogReportF_8: 3 Vector__XXX
 SG_ Monitor_NumberOfRefreshes : 8|8@1+ (1,0) [0|255] ""  Applications
 SG_ Monitor_EndReason : 0|8@1+ (1,0) [0|255] ""  Applications
 SG_ Monitor_FlagEqualisation : 16|1@1+ (1,0) [0|1] ""  Applications

BO_ 985 ModuleLogReportF_9: 3 Vector__XXX
 SG_ Monitor_NumberOfRefreshes : 8|8@1+ (1,0) [0|255] ""  Applications
 SG_ Monitor_EndReason : 0|8@1+ (1,0) [0|255] ""  Applications
 SG_ Monitor_FlagEqualisation : 16|1@1+ (1,0) [0|1] ""  Applications

BO_ 986 ModuleLogReportF_10: 3 Vector__XXX
 SG_ Monitor_NumberOfRefreshes : 8|8@1+ (1,0) [0|255] ""  Applications
 SG_ Monitor_EndReason : 0|8@1+ (1,0) [0|255] ""  Applications
 SG_ Monitor_FlagEqualisation : 16|1@1+ (1,0) [0|1] ""  Applications

BO_ 945 ModuleLogReportE_1: 8 OnBoardCharger_1
 SG_ Monitor_FloatTime : 0|16@1+ (1,0) [0|65535] "Minutes"  Applications
 SG_ Monitor_TimeRunningHot : 16|16@1+ (1,0) [0|65535] "Minutes"  Applications
 SG_ Monitor_MaxBatteryTemp : 56|8@1- (1,0) [-128|127] "C"  Applications
 SG_ Monitor_MaxVolts : 32|16@1+ (0.1,0) [0|0] "V"  Applications
 SG_ Monitor_StartBatteryTemp : 48|8@1- (1,0) [-128|127] "C"  Applications

BO_ 946 ModuleLogReportE_2: 8 Vector__XXX
 SG_ Monitor_FloatTime : 0|16@1+ (1,0) [0|65535] "Minutes"  Applications
 SG_ Monitor_TimeRunningHot : 16|16@1+ (1,0) [0|65535] "Minutes"  Applications
 SG_ Monitor_MaxBatteryTemp : 56|8@1- (1,0) [-128|127] "C"  Applications
 SG_ Monitor_MaxVolts : 32|16@1+ (0.1,0) [0|0] "V"  Applications
 SG_ Monitor_StartBatteryTemp : 48|8@1- (1,0) [-128|127] "C"  Applications

BO_ 947 ModuleLogReportE_3: 8 Vector__XXX
 SG_ Monitor_FloatTime : 0|16@1+ (1,0) [0|65535] "Minutes"  Applications
 SG_ Monitor_TimeRunningHot : 16|16@1+ (1,0) [0|65535] "Minutes"  Applications
 SG_ Monitor_MaxBatteryTemp : 56|8@1- (1,0) [-128|127] "C"  Applications
 SG_ Monitor_MaxVolts : 32|16@1+ (0.1,0) [0|0] "V"  Applications
 SG_ Monitor_StartBatteryTemp : 48|8@1- (1,0) [-128|127] "C"  Applications

BO_ 948 ModuleLogReportE_4: 8 Vector__XXX
 SG_ Monitor_FloatTime : 0|16@1+ (1,0) [0|65535] "Minutes"  Applications
 SG_ Monitor_TimeRunningHot : 16|16@1+ (1,0) [0|65535] "Minutes"  Applications
 SG_ Monitor_MaxBatteryTemp : 56|8@1- (1,0) [-128|127] "C"  Applications
 SG_ Monitor_MaxVolts : 32|16@1+ (0.1,0) [0|0] "V"  Applications
 SG_ Monitor_StartBatteryTemp : 48|8@1- (1,0) [-128|127] "C"  Applications

BO_ 949 ModuleLogReportE_5: 8 Vector__XXX
 SG_ Monitor_FloatTime : 0|16@1+ (1,0) [0|65535] "Minutes"  Applications
 SG_ Monitor_TimeRunningHot : 16|16@1+ (1,0) [0|65535] "Minutes"  Applications
 SG_ Monitor_MaxBatteryTemp : 56|8@1- (1,0) [-128|127] "C"  Applications
 SG_ Monitor_MaxVolts : 32|16@1+ (0.1,0) [0|0] "V"  Applications
 SG_ Monitor_StartBatteryTemp : 48|8@1- (1,0) [-128|127] "C"  Applications

BO_ 950 ModuleLogReportE_6: 8 Vector__XXX
 SG_ Monitor_FloatTime : 0|16@1+ (1,0) [0|65535] "Minutes"  Applications
 SG_ Monitor_TimeRunningHot : 16|16@1+ (1,0) [0|65535] "Minutes"  Applications
 SG_ Monitor_MaxBatteryTemp : 56|8@1- (1,0) [-128|127] "C"  Applications
 SG_ Monitor_MaxVolts : 32|16@1+ (0.1,0) [0|0] "V"  Applications
 SG_ Monitor_StartBatteryTemp : 48|8@1- (1,0) [-128|127] "C"  Applications

BO_ 951 ModuleLogReportE_7: 8 Vector__XXX
 SG_ Monitor_FloatTime : 0|16@1+ (1,0) [0|65535] "Minutes"  Applications
 SG_ Monitor_TimeRunningHot : 16|16@1+ (1,0) [0|65535] "Minutes"  Applications
 SG_ Monitor_MaxBatteryTemp : 56|8@1- (1,0) [-128|127] "C"  Applications
 SG_ Monitor_MaxVolts : 32|16@1+ (0.1,0) [0|0] "V"  Applications
 SG_ Monitor_StartBatteryTemp : 48|8@1- (1,0) [-128|127] "C"  Applications

BO_ 952 ModuleLogReportE_8: 8 Vector__XXX
 SG_ Monitor_FloatTime : 0|16@1+ (1,0) [0|65535] "Minutes"  Applications
 SG_ Monitor_TimeRunningHot : 16|16@1+ (1,0) [0|65535] "Minutes"  Applications
 SG_ Monitor_MaxBatteryTemp : 56|8@1- (1,0) [-128|127] "C"  Applications
 SG_ Monitor_MaxVolts : 32|16@1+ (0.1,0) [0|0] "V"  Applications
 SG_ Monitor_StartBatteryTemp : 48|8@1- (1,0) [-128|127] "C"  Applications

BO_ 953 ModuleLogReportE_9: 8 Vector__XXX
 SG_ Monitor_FloatTime : 0|16@1+ (1,0) [0|65535] "Minutes"  Applications
 SG_ Monitor_TimeRunningHot : 16|16@1+ (1,0) [0|65535] "Minutes"  Applications
 SG_ Monitor_MaxBatteryTemp : 56|8@1- (1,0) [-128|127] "C"  Applications
 SG_ Monitor_MaxVolts : 32|16@1+ (0.1,0) [0|0] "V"  Applications
 SG_ Monitor_StartBatteryTemp : 48|8@1- (1,0) [-128|127] "C"  Applications

BO_ 954 ModuleLogReportE_10: 8 Vector__XXX
 SG_ Monitor_FloatTime : 0|16@1+ (1,0) [0|65535] "Minutes"  Applications
 SG_ Monitor_TimeRunningHot : 16|16@1+ (1,0) [0|65535] "Minutes"  Applications
 SG_ Monitor_MaxBatteryTemp : 56|8@1- (1,0) [-128|127] "C"  Applications
 SG_ Monitor_MaxVolts : 32|16@1+ (0.1,0) [0|0] "V"  Applications
 SG_ Monitor_StartBatteryTemp : 48|8@1- (1,0) [-128|127] "C"  Applications

BO_ 929 ModuleLogReportD_1: 8 OnBoardCharger_1
 SG_ Monitor_ProfileID : 32|32@1+ (1,0) [0|65535] ""  Applications
 SG_ Monitor_Timestamp : 0|32@1+ (1,0) [0|4294967295] "Seconds"  Applications

BO_ 930 ModuleLogReportD_2: 8 Vector__XXX
 SG_ Monitor_ProfileID : 32|32@1+ (1,0) [0|65535] ""  Applications
 SG_ Monitor_Timestamp : 0|32@1+ (1,0) [0|4294967295] "Seconds"  Applications

BO_ 931 ModuleLogReportD_3: 8 Vector__XXX
 SG_ Monitor_ProfileID : 32|32@1+ (1,0) [0|65535] ""  Applications
 SG_ Monitor_Timestamp : 0|32@1+ (1,0) [0|4294967295] "Seconds"  Applications

BO_ 932 ModuleLogReportD_4: 8 Vector__XXX
 SG_ Monitor_ProfileID : 32|32@1+ (1,0) [0|65535] ""  Applications
 SG_ Monitor_Timestamp : 0|32@1+ (1,0) [0|4294967295] "Seconds"  Applications

BO_ 933 ModuleLogReportD_5: 8 Vector__XXX
 SG_ Monitor_ProfileID : 32|32@1+ (1,0) [0|65535] ""  Applications
 SG_ Monitor_Timestamp : 0|32@1+ (1,0) [0|4294967295] "Seconds"  Applications

BO_ 934 ModuleLogReportD_6: 8 Vector__XXX
 SG_ Monitor_ProfileID : 32|32@1+ (1,0) [0|65535] ""  Applications
 SG_ Monitor_Timestamp : 0|32@1+ (1,0) [0|4294967295] "Seconds"  Applications

BO_ 935 ModuleLogReportD_7: 8 Vector__XXX
 SG_ Monitor_ProfileID : 32|32@1+ (1,0) [0|65535] ""  Applications
 SG_ Monitor_Timestamp : 0|32@1+ (1,0) [0|4294967295] "Seconds"  Applications

BO_ 936 ModuleLogReportD_8: 8 Vector__XXX
 SG_ Monitor_ProfileID : 32|32@1+ (1,0) [0|65535] ""  Applications
 SG_ Monitor_Timestamp : 0|32@1+ (1,0) [0|4294967295] "Seconds"  Applications

BO_ 937 ModuleLogReportD_9: 8 Vector__XXX
 SG_ Monitor_ProfileID : 32|32@1+ (1,0) [0|65535] ""  Applications
 SG_ Monitor_Timestamp : 0|32@1+ (1,0) [0|4294967295] "Seconds"  Applications

BO_ 938 ModuleLogReportD_10: 8 Vector__XXX
 SG_ Monitor_ProfileID : 32|32@1+ (1,0) [0|65535] ""  Applications
 SG_ Monitor_Timestamp : 0|32@1+ (1,0) [0|4294967295] "Seconds"  Applications

BO_ 1872 ConfigurationReportD_T: 1 OnBoardChargerTemplate
 SG_ Config_SelectedProfile : 0|8@1+ (1,0) [0|0] "" Vector__XXX

BO_ 1664 Config_SetConfigurationD: 2 Applications
 SG_ Config_Save_SelectedProfile : 8|1@1+ (1,0) [0|1] ""  WirelessCharger_1,WirelessChargerTemplate,OnBoardCharger_1,OnBoardChargerTemplate
 SG_ Config_SelectedProfile : 0|8@1+ (1,0) [0|0] ""  WirelessCharger_1,WirelessChargerTemplate,OnBoardCharger_1,OnBoardChargerTemplate

BO_ 1648 Config_SetConfigurationC: 3 Applications
 SG_ Config_Save_CableResistance : 16|1@1+ (1,0) [0|1] ""  WirelessCharger_1,WirelessChargerTemplate,OnBoardCharger_1,OnBoardChargerTemplate
 SG_ Config_CableResistance : 0|16@1+ (0.1,0) [0|6553.5] "mOhm"  WirelessCharger_1,WirelessChargerTemplate,OnBoardCharger_1,OnBoardChargerTemplate

BO_ 1856 ConfigurationReportC_T: 2 OnBoardChargerTemplate
 SG_ Report_CableResistance : 0|16@1+ (0.1,0) [0|6553.5] "mOhm" Vector__XXX

BO_ 1760 ProfileLoadCompleteAck_T: 8 OnBoardChargerTemplate
 SG_ ProfileAckNackComplete_T : 0|8@1+ (1,0) [0|0] "" Vector__XXX

BO_ 1744 ProfileLoadDataAck_T: 8 OnBoardChargerTemplate
 SG_ ProfileMessageSequence_T : 8|5@1+ (1,0) [0|31] "" Vector__XXX
 SG_ ProfileAckNackData_T : 0|8@1+ (1,0) [0|0] "" Vector__XXX

BO_ 1728 ProfileLoadRequestAck_T: 8 OnBoardChargerTemplate
 SG_ ProfileAckNackRequest_T : 0|8@1+ (1,0) [0|0] "" Vector__XXX

BO_ 1712 ProfileLoadComplete: 8 Applications
 SG_ ProfileCrc : 0|16@1+ (1,0) [0|65535] ""  WirelessCharger_1,WirelessChargerTemplate,OnBoardCharger_1,OnBoardChargerTemplate

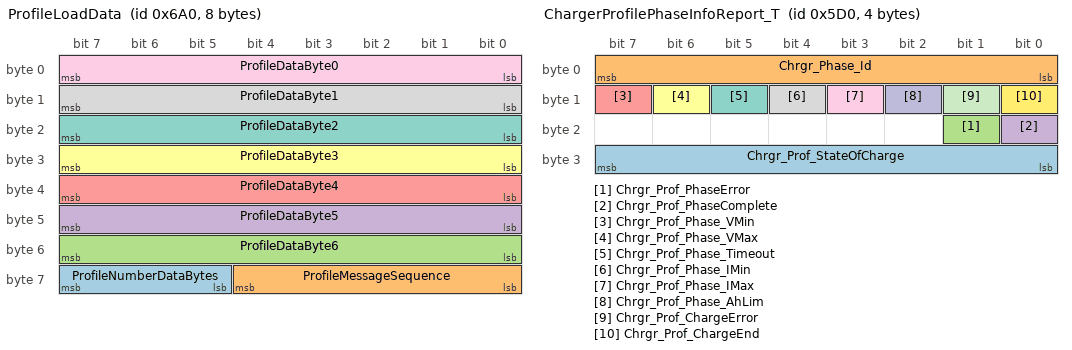
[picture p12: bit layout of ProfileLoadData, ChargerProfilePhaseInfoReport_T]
BO_ 1696 ProfileLoadData: 8 Applications
 SG_ ProfileNumberDataBytes : 61|3@1+ (1,0) [0|7] ""  WirelessCharger_1,WirelessChargerTemplate,OnBoardCharger_1,OnBoardChargerTemplate
 SG_ ProfileMessageSequence : 56|5@1+ (1,0) [0|31] ""  WirelessCharger_1,WirelessChargerTemplate,OnBoardCharger_1,OnBoardChargerTemplate
 SG_ ProfileDataByte6 : 48|8@1+ (1,0) [0|255] ""  WirelessCharger_1,WirelessChargerTemplate,OnBoardCharger_1,OnBoardChargerTemplate
 SG_ ProfileDataByte5 : 40|8@1+ (1,0) [0|255] ""  WirelessCharger_1,WirelessChargerTemplate,OnBoardCharger_1,OnBoardChargerTemplate
 SG_ ProfileDataByte4 : 32|8@1+ (1,0) [0|255] ""  WirelessCharger_1,WirelessChargerTemplate,OnBoardCharger_1,OnBoardChargerTemplate
 SG_ ProfileDataByte3 : 24|8@1+ (1,0) [0|255] ""  WirelessCharger_1,WirelessChargerTemplate,OnBoardCharger_1,OnBoardChargerTemplate
 SG_ ProfileDataByte2 : 16|8@1+ (1,0) [0|255] ""  WirelessCharger_1,WirelessChargerTemplate,OnBoardCharger_1,OnBoardChargerTemplate
 SG_ ProfileDataByte1 : 8|8@1+ (1,0) [0|255] ""  WirelessCharger_1,WirelessChargerTemplate,OnBoardCharger_1,OnBoardChargerTemplate
 SG_ ProfileDataByte0 : 0|8@1+ (1,0) [0|255] ""  WirelessCharger_1,WirelessChargerTemplate,OnBoardCharger_1,OnBoardChargerTemplate

BO_ 1680 ProfileLoadRequest: 8 Applications
 SG_ ProfileAlgorithmVersion : 8|8@1+ (1,0) [0|255] ""  WirelessCharger_1,WirelessChargerTemplate,OnBoardCharger_1,OnBoardChargerTemplate
 SG_ ProfileSwitchPosition : 0|4@1+ (1,0) [1|15] ""  WirelessCharger_1,WirelessChargerTemplate,OnBoardCharger_1,OnBoardChargerTemplate

BO_ 1488 ChargerProfilePhaseInfoReport_T: 4 OnBoardChargerTemplate
 SG_ Chrgr_Prof_StateOfCharge : 24|8@1+ (1,0) [0|100] "" Vector__XXX
 SG_ Chrgr_Phase_Id : 0|8@1- (1,0) [-128|127] "" Vector__XXX
 SG_ Chrgr_Prof_PhaseError : 17|1@1+ (1,0) [0|1] "" Vector__XXX
 SG_ Chrgr_Prof_PhaseComplete : 16|1@1+ (1,0) [0|1] "" Vector__XXX
 SG_ Chrgr_Prof_Phase_VMin : 15|1@1+ (1,0) [0|1] "" Vector__XXX
 SG_ Chrgr_Prof_Phase_VMax : 14|1@1+ (1,0) [0|1] "" Vector__XXX
 SG_ Chrgr_Prof_Phase_Timeout : 13|1@1+ (1,0) [0|1] "" Vector__XXX
 SG_ Chrgr_Prof_Phase_IMin : 12|1@1+ (1,0) [0|1] "" Vector__XXX
 SG_ Chrgr_Prof_Phase_IMax : 11|1@1+ (1,0) [0|1] "" Vector__XXX
 SG_ Chrgr_Prof_Phase_AhLim : 10|1@1+ (1,0) [0|1] "" Vector__XXX
 SG_ Chrgr_Prof_ChargeError : 9|1@1+ (1,0) [0|1] "" Vector__XXX
 SG_ Chrgr_Prof_ChargeEnd : 8|1@1+ (1,0) [0|1] "" Vector__XXX

BO_ 1472 ChargerProfileInfoReport_T: 5 OnBoardChargerTemplate
 SG_ Chrgr_Prof_SelectorSwitch : 32|4@1+ (1,0) [0|15] "" Vector__XXX
 SG_ Chrgr_Prof_Id : 0|32@1+ (1,0) [0|4294967295] "" Vector__XXX

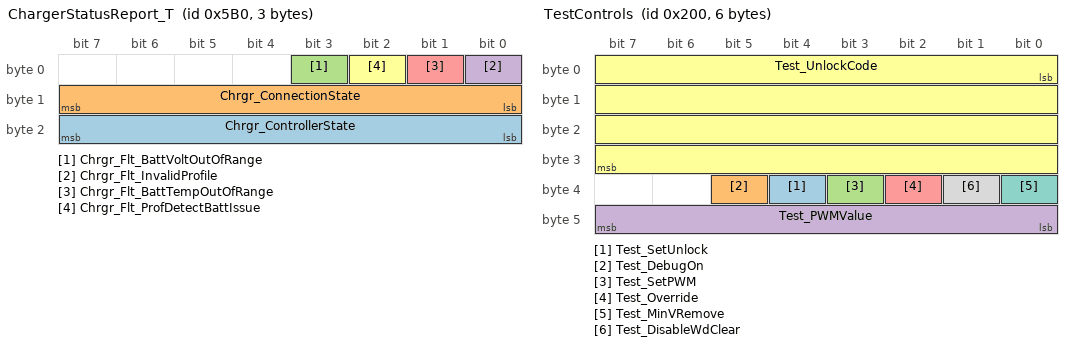
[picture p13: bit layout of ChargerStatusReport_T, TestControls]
BO_ 1456 ChargerStatusReport_T: 3 OnBoardChargerTemplate
 SG_ Chrgr_ControllerState : 16|8@1+ (1,0) [0|0] "" Vector__XXX
 SG_ Chrgr_ConnectionState : 8|8@1+ (1,0) [0|0] "" Vector__XXX
 SG_ Chrgr_Flt_BattVoltOutOfRange : 3|1@1+ (1,0) [0|1] "" Vector__XXX
 SG_ Chrgr_Flt_InvalidProfile : 0|1@1+ (1,0) [0|1] "" Vector__XXX
 SG_ Chrgr_Flt_BattTempOutOfRange : 1|1@1+ (1,0) [0|1] "" Vector__XXX
 SG_ Chrgr_Flt_ProfDetectBattIssue : 2|1@1+ (1,0) [0|1] "" Vector__XXX

BO_ 1440 ChargerMeasurementsReport_T: 8 OnBoardChargerTemplate
 SG_ Charger_CalculatedBatteryVoltage : 32|32@1+ (0.0009765625,0) [0|4194303.99902344] "V" Vector__XXX
 SG_ ChargerBatteryTemperature : 16|16@1- (0.005,0) [-163.84|163.835] "C" Vector__XXX
 SG_ ChargerTemperature : 0|16@1- (0.005,0) [-163.84|163.835] "C" Vector__XXX

BO_ 976 ModuleLogReportF_T: 3 OnBoardChargerTemplate
 SG_ Monitor_NumberOfRefreshes : 8|8@1+ (1,0) [0|255] "" Vector__XXX
 SG_ Monitor_EndReason : 0|8@1+ (1,0) [0|255] "" Vector__XXX
 SG_ Monitor_FlagEqualisation : 16|1@1+ (1,0) [0|1] "" Vector__XXX

BO_ 944 ModuleLogReportE_T: 8 OnBoardChargerTemplate
 SG_ Monitor_FloatTime : 0|16@1+ (1,0) [0|65535] "Minutes" Vector__XXX
 SG_ Monitor_TimeRunningHot : 16|16@1+ (1,0) [0|65535] "Minutes" Vector__XXX
 SG_ Monitor_MaxBatteryTemp : 56|8@1- (1,0) [-128|127] "C" Vector__XXX
 SG_ Monitor_MaxVolts : 32|16@1+ (0.1,0) [0|0] "V" Vector__XXX
 SG_ Monitor_StartBatteryTemp : 48|8@1- (1,0) [-128|127] "C" Vector__XXX

BO_ 928 ModuleLogReportD_T: 8 OnBoardChargerTemplate
 SG_ Monitor_ProfileID : 32|32@1+ (1,0) [0|65535] "" Vector__XXX
 SG_ Monitor_Timestamp : 0|32@1+ (1,0) [0|4294967295] "Seconds" Vector__XXX

BO_ 409 ControlModule_9: 6 SystemController
 SG_ Demand_PowerStage_9 : 20|1@1+ (1,0) [0|1] ""  Applications,OnBoardChargerTemplate,PowerModuleTemplate,PowerModule_9
 SG_ Demand_ClearFaults_9 : 21|1@1+ (1,0) [0|1] ""  Applications,OnBoardChargerTemplate,PowerModuleTemplate,PowerModule_9
 SG_ Demand_Voltage_9 : 0|20@1+ (0.001,0) [0|1048.575] "Volts"  Applications,OnBoardChargerTemplate,PowerModuleTemplate,PowerModule_9
 SG_ Demand_Current_9 : 24|18@1+ (0.001,0) [0|262.143] "Amps"  Applications,OnBoardChargerTemplate,PowerModuleTemplate,PowerModule_9

BO_ 408 ControlModule_8: 6 SystemController
 SG_ Demand_PowerStage_8 : 20|1@1+ (1,0) [0|1] ""  Applications,OnBoardChargerTemplate,PowerModuleTemplate,PowerModule_8
 SG_ Demand_ClearFaults_8 : 21|1@1+ (1,0) [0|1] ""  Applications,OnBoardChargerTemplate,PowerModuleTemplate,PowerModule_8
 SG_ Demand_Voltage_8 : 0|20@1+ (0.001,0) [0|1048.575] "Volts"  Applications,OnBoardChargerTemplate,PowerModuleTemplate,PowerModule_8
 SG_ Demand_Current_8 : 24|18@1+ (0.001,0) [0|262.143] "Amps"  Applications,OnBoardChargerTemplate,PowerModuleTemplate,PowerModule_8

BO_ 407 ControlModule_7: 6 SystemController
 SG_ Demand_PowerStage_7 : 20|1@1+ (1,0) [0|1] ""  Applications,OnBoardChargerTemplate,PowerModuleTemplate,PowerModule_7
 SG_ Demand_ClearFaults_7 : 21|1@1+ (1,0) [0|1] ""  Applications,OnBoardChargerTemplate,PowerModuleTemplate,PowerModule_7
 SG_ Demand_Voltage_7 : 0|20@1+ (0.001,0) [0|1048.575] "Volts"  Applications,OnBoardChargerTemplate,PowerModuleTemplate,PowerModule_7
 SG_ Demand_Current_7 : 24|18@1+ (0.001,0) [0|262.143] "Amps"  Applications,OnBoardChargerTemplate,PowerModuleTemplate,PowerModule_7

BO_ 406 ControlModule_6: 6 SystemController
 SG_ Demand_PowerStage_6 : 20|1@1+ (1,0) [0|1] ""  Applications,OnBoardChargerTemplate,PowerModuleTemplate,PowerModule_6
 SG_ Demand_ClearFaults_6 : 21|1@1+ (1,0) [0|1] ""  Applications,OnBoardChargerTemplate,PowerModuleTemplate,PowerModule_6
 SG_ Demand_Voltage_6 : 0|20@1+ (0.001,0) [0|1048.575] "Volts"  Applications,OnBoardChargerTemplate,PowerModuleTemplate,PowerModule_6
 SG_ Demand_Current_6 : 24|18@1+ (0.001,0) [0|262.143] "Amps"  Applications,OnBoardChargerTemplate,PowerModuleTemplate,PowerModule_6

BO_ 405 ControlModule_5: 6 SystemController
 SG_ Demand_PowerStage_5 : 20|1@1+ (1,0) [0|1] ""  Applications,OnBoardChargerTemplate,PowerModuleTemplate,PowerModule_5
 SG_ Demand_ClearFaults_5 : 21|1@1+ (1,0) [0|1] ""  Applications,OnBoardChargerTemplate,PowerModuleTemplate,PowerModule_5
 SG_ Demand_Voltage_5 : 0|20@1+ (0.001,0) [0|1048.575] "Volts"  Applications,OnBoardChargerTemplate,PowerModuleTemplate,PowerModule_5
 SG_ Demand_Current_5 : 24|18@1+ (0.001,0) [0|262.143] "Amps"  Applications,OnBoardChargerTemplate,PowerModuleTemplate,PowerModule_5

BO_ 404 ControlModule_4: 6 SystemController
 SG_ Demand_PowerStage_4 : 20|1@1+ (1,0) [0|1] ""  Applications,OnBoardChargerTemplate,PowerModuleTemplate,PowerModule_4
 SG_ Demand_ClearFaults_4 : 21|1@1+ (1,0) [0|1] ""  Applications,OnBoardChargerTemplate,PowerModuleTemplate,PowerModule_4
 SG_ Demand_Voltage_4 : 0|20@1+ (0.001,0) [0|1048.575] "Volts"  Applications,OnBoardChargerTemplate,PowerModuleTemplate,PowerModule_4
 SG_ Demand_Current_4 : 24|18@1+ (0.001,0) [0|262.143] "Amps"  Applications,OnBoardChargerTemplate,PowerModuleTemplate,PowerModule_4

BO_ 403 ControlModule_3: 6 SystemController
 SG_ Demand_PowerStage_3 : 20|1@1+ (1,0) [0|1] ""  Applications,OnBoardChargerTemplate,PowerModuleTemplate,PowerModule_3
 SG_ Demand_ClearFaults_3 : 21|1@1+ (1,0) [0|1] ""  Applications,OnBoardChargerTemplate,PowerModuleTemplate,PowerModule_3
 SG_ Demand_Voltage_3 : 0|20@1+ (0.001,0) [0|1048.575] "Volts"  Applications,OnBoardChargerTemplate,PowerModuleTemplate,PowerModule_3
 SG_ Demand_Current_3 : 24|18@1+ (0.001,0) [0|262.143] "Amps"  Applications,OnBoardChargerTemplate,PowerModuleTemplate,PowerModule_3

BO_ 402 ControlModule_2: 6 SystemController
 SG_ Demand_PowerStage_2 : 20|1@1+ (1,0) [0|1] ""  Applications,OnBoardChargerTemplate,PowerModuleTemplate,PowerModule_2
 SG_ Demand_ClearFaults_2 : 21|1@1+ (1,0) [0|1] ""  Applications,OnBoardChargerTemplate,PowerModuleTemplate,PowerModule_2
 SG_ Demand_Voltage_2 : 0|20@1+ (0.001,0) [0|1048.575] "Volts"  Applications,OnBoardChargerTemplate,PowerModuleTemplate,PowerModule_2
 SG_ Demand_Current_2 : 24|18@1+ (0.001,0) [0|262.143] "Amps"  Applications,OnBoardChargerTemplate,PowerModuleTemplate,PowerModule_2

BO_ 410 ControlModule_10: 6 SystemController
 SG_ Demand_PowerStage_10 : 20|1@1+ (1,0) [0|1] ""  Applications,OnBoardChargerTemplate,PowerModuleTemplate,PowerModule_10
 SG_ Demand_ClearFaults_10 : 21|1@1+ (1,0) [0|1] ""  Applications,OnBoardChargerTemplate,PowerModuleTemplate,PowerModule_10
 SG_ Demand_Voltage_10 : 0|20@1+ (0.001,0) [0|1048.575] "Volts"  Applications,OnBoardChargerTemplate,PowerModuleTemplate,PowerModule_10
 SG_ Demand_Current_10 : 24|18@1+ (0.001,0) [0|262.143] "Amps"  Applications,OnBoardChargerTemplate,PowerModuleTemplate,PowerModule_10

BO_ 401 ControlModule_1: 6 SystemController
 SG_ Demand_ClearFaults_1 : 21|1@1+ (1,0) [0|1] ""  Applications,OnBoardCharger_1,OnBoardChargerTemplate,PowerModuleTemplate,PowerModule_1
 SG_ Demand_PowerStage_1 : 20|1@1+ (1,0) [0|1] ""  Applications,OnBoardCharger_1,OnBoardChargerTemplate,PowerModuleTemplate,PowerModule_1
 SG_ Demand_Voltage_1 : 0|20@1+ (0.001,0) [0|1048.575] "Volts"  Applications,OnBoardCharger_1,OnBoardChargerTemplate,PowerModuleTemplate,PowerModule_1
 SG_ Demand_Current_1 : 24|18@1+ (0.001,0) [0|262.143] "Amps"  Applications,OnBoardCharger_1,OnBoardChargerTemplate,PowerModuleTemplate,PowerModule_1

BO_ 512 TestControls: 6 Applications
 SG_ Test_SetUnlock : 36|1@1+ (1,0) [0|1] ""  OnBoardCharger_1,OnBoardChargerTemplate,PowerModuleTemplate,WirelessCharger_1,WirelessChargerTemplate
 SG_ Test_DebugOn : 37|1@1+ (1,0) [0|1] ""  OnBoardCharger_1,OnBoardChargerTemplate,PowerModuleTemplate,WirelessCharger_1,WirelessChargerTemplate
 SG_ Test_SetPWM : 35|1@1+ (1,0) [0|1] ""  WirelessCharger_1,WirelessChargerTemplate,PowerModuleTemplate,OnBoardChargerTemplate,OnBoardCharger_1
 SG_ Test_PWMValue : 40|8@1+ (0.5,0) [0|100] ""  WirelessCharger_1,WirelessChargerTemplate,PowerModuleTemplate,OnBoardChargerTemplate,OnBoardCharger_1
 SG_ Test_Override : 34|1@1+ (1,0) [0|1] ""  WirelessCharger_1,WirelessChargerTemplate,OnBoardCharger_1,OnBoardChargerTemplate,PowerModuleTemplate
 SG_ Test_UnlockCode : 0|32@1+ (1,0) [0|4294967295] ""  WirelessCharger_1,WirelessChargerTemplate,OnBoardCharger_1,OnBoardChargerTemplate,PowerModuleTemplate
 SG_ Test_MinVRemove : 32|1@1+ (1,0) [0|1] ""  WirelessCharger_1,WirelessChargerTemplate,OnBoardCharger_1,OnBoardChargerTemplate,PowerModuleTemplate
 SG_ Test_DisableWdClear : 33|1@1+ (1,0) [0|1] ""  WirelessCharger_1,WirelessChargerTemplate,OnBoardCharger_1,OnBoardChargerTemplate,PowerModuleTemplate

BO_ 970 ModuleACMeasurements_10: 6 PowerModule_10
 SG_ Report_Meas_Frequency_AC : 38|10@1+ (0.1,0) [0|102.3] "Hz"  Applications
 SG_ Report_Meas_Voltage_AC : 0|20@1+ (0.001,0) [0|1048.575] "V"  Applications
 SG_ Report_Meas_Current_AC : 20|18@1+ (0.001,0) [0|262.143] "A"  Applications

BO_ 969 ModuleACMeasurements_9: 6 PowerModule_9
 SG_ Report_Meas_Frequency_AC : 38|10@1+ (0.1,0) [0|102.3] "Hz"  Applications
 SG_ Report_Meas_Voltage_AC : 0|20@1+ (0.001,0) [0|1048.575] "V"  Applications
 SG_ Report_Meas_Current_AC : 20|18@1+ (0.001,0) [0|262.143] "A"  Applications

BO_ 968 ModuleACMeasurements_8: 6 PowerModule_8
 SG_ Report_Meas_Frequency_AC : 38|10@1+ (0.1,0) [0|102.3] "Hz"  Applications
 SG_ Report_Meas_Voltage_AC : 0|20@1+ (0.001,0) [0|1048.575] "V"  Applications
 SG_ Report_Meas_Current_AC : 20|18@1+ (0.001,0) [0|262.143] "A"  Applications

BO_ 967 ModuleACMeasurements_7: 6 PowerModule_7
 SG_ Report_Meas_Frequency_AC : 38|10@1+ (0.1,0) [0|102.3] "Hz"  Applications
 SG_ Report_Meas_Voltage_AC : 0|20@1+ (0.001,0) [0|1048.575] "V"  Applications
 SG_ Report_Meas_Current_AC : 20|18@1+ (0.001,0) [0|262.143] "A"  Applications

BO_ 966 ModuleACMeasurements_6: 6 PowerModule_6
 SG_ Report_Meas_Frequency_AC : 38|10@1+ (0.1,0) [0|102.3] "Hz"  Applications
 SG_ Report_Meas_Voltage_AC : 0|20@1+ (0.001,0) [0|1048.575] "V"  Applications
 SG_ Report_Meas_Current_AC : 20|18@1+ (0.001,0) [0|262.143] "A"  Applications

BO_ 965 ModuleACMeasurements_5: 6 PowerModule_5
 SG_ Report_Meas_Frequency_AC : 38|10@1+ (0.1,0) [0|102.3] "Hz"  Applications
 SG_ Report_Meas_Voltage_AC : 0|20@1+ (0.001,0) [0|1048.575] "V"  Applications
 SG_ Report_Meas_Current_AC : 20|18@1+ (0.001,0) [0|262.143] "A"  Applications

BO_ 964 ModuleACMeasurements_4: 6 PowerModule_4
 SG_ Report_Meas_Frequency_AC : 38|10@1+ (0.1,0) [0|102.3] "Hz"  Applications
 SG_ Report_Meas_Voltage_AC : 0|20@1+ (0.001,0) [0|1048.575] "V"  Applications
 SG_ Report_Meas_Current_AC : 20|18@1+ (0.001,0) [0|262.143] "A"  Applications

BO_ 963 ModuleACMeasurements_3: 6 PowerModule_3
 SG_ Report_Meas_Frequency_AC : 38|10@1+ (0.1,0) [0|102.3] "Hz"  Applications
 SG_ Report_Meas_Voltage_AC : 0|20@1+ (0.001,0) [0|1048.575] "V"  Applications
 SG_ Report_Meas_Current_AC : 20|18@1+ (0.001,0) [0|262.143] "A"  Applications

BO_ 962 ModuleACMeasurements_2: 6 PowerModule_2
 SG_ Report_Meas_Frequency_AC : 38|10@1+ (0.1,0) [0|102.3] "Hz"  Applications
 SG_ Report_Meas_Voltage_AC : 0|20@1+ (0.001,0) [0|1048.575] "V"  Applications
 SG_ Report_Meas_Current_AC : 20|18@1+ (0.001,0) [0|262.143] "A"  Applications

BO_ 961 ModuleACMeasurements_1: 6 PowerModule_1
 SG_ Report_Meas_Frequency_AC : 38|10@1+ (0.1,0) [0|102.3] "Hz"  Applications
 SG_ Report_Meas_Voltage_AC : 0|20@1+ (0.001,0) [0|1048.575] "V"  Applications
 SG_ Report_Meas_Current_AC : 20|18@1+ (0.001,0) [0|262.143] "A"  Applications

BO_ 960 ModuleACMeasurements_T: 6 PowerModuleTemplate
 SG_ Report_Meas_Frequency_AC : 38|10@1+ (0.1,0) [0|102.3] "Hz" Vector__XXX
 SG_ Report_Meas_Voltage_AC : 0|20@1+ (0.001,0) [0|1048.575] "V" Vector__XXX
 SG_ Report_Meas_Current_AC : 20|18@1+ (0.001,0) [0|262.143] "A" Vector__XXX

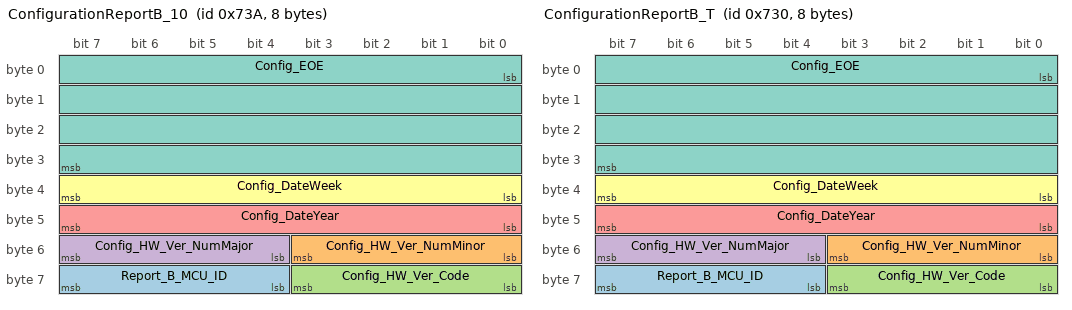
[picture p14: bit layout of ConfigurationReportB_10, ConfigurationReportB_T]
BO_ 1850 ConfigurationReportB_10: 8 PowerModule_10
 SG_ Report_B_MCU_ID : 60|4@1+ (1,0) [0|15] ""  SystemController,Applications
 SG_ Config_HW_Ver_NumMinor : 48|4@1+ (1,0) [0|15] ""  SystemController,Applications
 SG_ Config_HW_Ver_Code : 56|4@1+ (1,0) [0|15] ""  SystemController,Applications
 SG_ Config_HW_Ver_NumMajor : 52|4@1+ (1,0) [0|15] ""  SystemController,Applications
 SG_ Config_DateYear : 40|8@1+ (1,0) [0|255] "YY"  SystemController,Applications
 SG_ Config_DateWeek : 32|8@1+ (1,0) [0|255] "WW"  SystemController,Applications
 SG_ Config_EOE : 0|32@1+ (1,0) [0|4294967295] ""  SystemController,Applications

BO_ 1840 ConfigurationReportB_T: 8 PowerModuleTemplate
 SG_ Report_B_MCU_ID : 60|4@1+ (1,0) [0|15] "" Vector__XXX
 SG_ Config_HW_Ver_NumMinor : 48|4@1+ (1,0) [0|15] "" Vector__XXX
 SG_ Config_HW_Ver_Code : 56|4@1+ (1,0) [0|15] "" Vector__XXX
 SG_ Config_HW_Ver_NumMajor : 52|4@1+ (1,0) [0|15] "" Vector__XXX
 SG_ Config_DateYear : 40|8@1+ (1,0) [0|255] "YY" Vector__XXX
 SG_ Config_DateWeek : 32|8@1+ (1,0) [0|255] "WW" Vector__XXX
 SG_ Config_EOE : 0|32@1+ (1,0) [0|4294967295] "" Vector__XXX

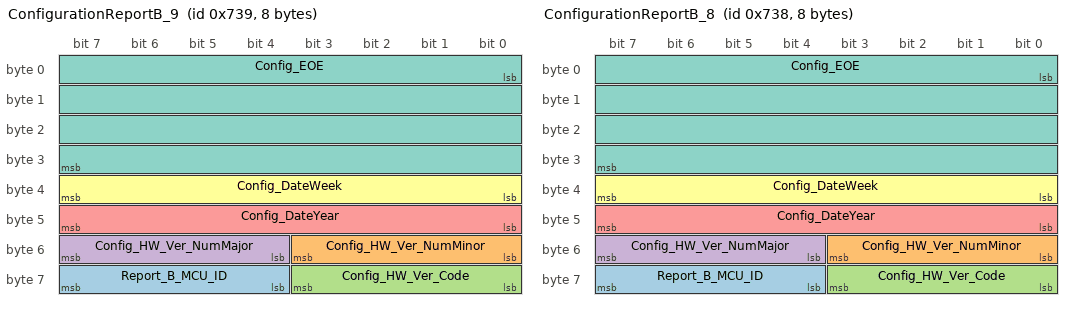
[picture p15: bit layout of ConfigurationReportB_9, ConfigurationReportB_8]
BO_ 1849 ConfigurationReportB_9: 8 PowerModule_9
 SG_ Report_B_MCU_ID : 60|4@1+ (1,0) [0|15] ""  SystemController,Applications
 SG_ Config_HW_Ver_NumMinor : 48|4@1+ (1,0) [0|15] ""  SystemController,Applications
 SG_ Config_HW_Ver_Code : 56|4@1+ (1,0) [0|15] ""  SystemController,Applications
 SG_ Config_HW_Ver_NumMajor : 52|4@1+ (1,0) [0|15] ""  SystemController,Applications
 SG_ Config_DateYear : 40|8@1+ (1,0) [0|255] "YY"  SystemController,Applications
 SG_ Config_DateWeek : 32|8@1+ (1,0) [0|255] "WW"  SystemController,Applications
 SG_ Config_EOE : 0|32@1+ (1,0) [0|4294967295] ""  SystemController,Applications

BO_ 1848 ConfigurationReportB_8: 8 PowerModule_8
 SG_ Report_B_MCU_ID : 60|4@1+ (1,0) [0|15] ""  SystemController,Applications
 SG_ Config_HW_Ver_NumMinor : 48|4@1+ (1,0) [0|15] ""  SystemController,Applications
 SG_ Config_HW_Ver_Code : 56|4@1+ (1,0) [0|15] ""  SystemController,Applications
 SG_ Config_HW_Ver_NumMajor : 52|4@1+ (1,0) [0|15] ""  SystemController,Applications
 SG_ Config_DateYear : 40|8@1+ (1,0) [0|255] "YY"  SystemController,Applications
 SG_ Config_DateWeek : 32|8@1+ (1,0) [0|255] "WW"  SystemController,Applications
 SG_ Config_EOE : 0|32@1+ (1,0) [0|4294967295] ""  SystemController,Applications

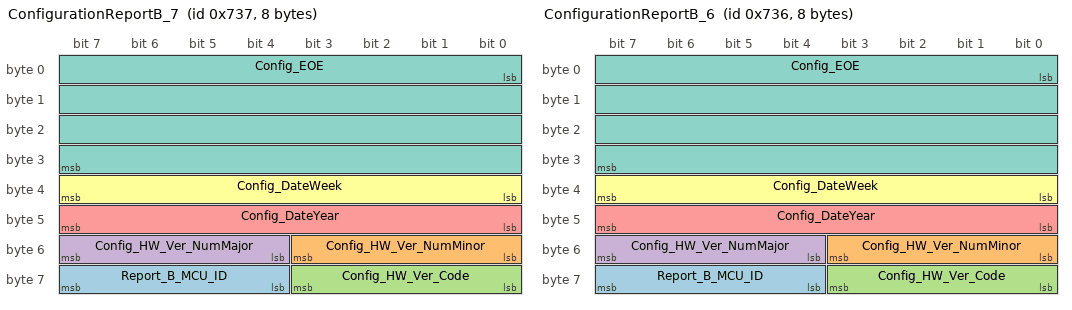
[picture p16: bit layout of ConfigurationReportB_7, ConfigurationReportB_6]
BO_ 1847 ConfigurationReportB_7: 8 PowerModule_7
 SG_ Report_B_MCU_ID : 60|4@1+ (1,0) [0|15] ""  SystemController,Applications
 SG_ Config_HW_Ver_NumMinor : 48|4@1+ (1,0) [0|15] ""  SystemController,Applications
 SG_ Config_HW_Ver_Code : 56|4@1+ (1,0) [0|15] ""  SystemController,Applications
 SG_ Config_HW_Ver_NumMajor : 52|4@1+ (1,0) [0|15] ""  SystemController,Applications
 SG_ Config_DateYear : 40|8@1+ (1,0) [0|255] "YY"  SystemController,Applications
 SG_ Config_DateWeek : 32|8@1+ (1,0) [0|255] "WW"  SystemController,Applications
 SG_ Config_EOE : 0|32@1+ (1,0) [0|4294967295] ""  SystemController,Applications

BO_ 1846 ConfigurationReportB_6: 8 PowerModule_6
 SG_ Report_B_MCU_ID : 60|4@1+ (1,0) [0|15] ""  SystemController,Applications
 SG_ Config_HW_Ver_NumMinor : 48|4@1+ (1,0) [0|15] ""  SystemController,Applications
 SG_ Config_HW_Ver_Code : 56|4@1+ (1,0) [0|15] ""  SystemController,Applications
 SG_ Config_HW_Ver_NumMajor : 52|4@1+ (1,0) [0|15] ""  SystemController,Applications
 SG_ Config_DateYear : 40|8@1+ (1,0) [0|255] "YY"  SystemController,Applications
 SG_ Config_DateWeek : 32|8@1+ (1,0) [0|255] "WW"  SystemController,Applications
 SG_ Config_EOE : 0|32@1+ (1,0) [0|4294967295] ""  SystemController,Applications

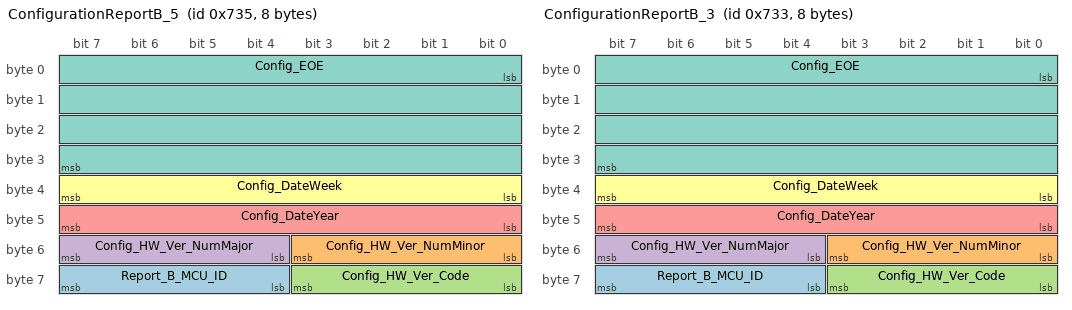
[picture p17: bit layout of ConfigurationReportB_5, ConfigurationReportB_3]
BO_ 1845 ConfigurationReportB_5: 8 PowerModule_5
 SG_ Report_B_MCU_ID : 60|4@1+ (1,0) [0|15] ""  SystemController,Applications
 SG_ Config_HW_Ver_NumMinor : 48|4@1+ (1,0) [0|15] ""  SystemController,Applications
 SG_ Config_HW_Ver_Code : 56|4@1+ (1,0) [0|15] ""  SystemController,Applications
 SG_ Config_HW_Ver_NumMajor : 52|4@1+ (1,0) [0|15] ""  SystemController,Applications
 SG_ Config_DateYear : 40|8@1+ (1,0) [0|255] "YY"  SystemController,Applications
 SG_ Config_DateWeek : 32|8@1+ (1,0) [0|255] "WW"  SystemController,Applications
 SG_ Config_EOE : 0|32@1+ (1,0) [0|4294967295] ""  SystemController,Applications

BO_ 1843 ConfigurationReportB_3: 8 PowerModule_3
 SG_ Report_B_MCU_ID : 60|4@1+ (1,0) [0|15] ""  SystemController,Applications
 SG_ Config_HW_Ver_NumMinor : 48|4@1+ (1,0) [0|15] ""  SystemController,Applications
 SG_ Config_HW_Ver_Code : 56|4@1+ (1,0) [0|15] ""  SystemController,Applications
 SG_ Config_HW_Ver_NumMajor : 52|4@1+ (1,0) [0|15] ""  SystemController,Applications
 SG_ Config_DateYear : 40|8@1+ (1,0) [0|255] "YY"  SystemController,Applications
 SG_ Config_DateWeek : 32|8@1+ (1,0) [0|255] "WW"  SystemController,Applications
 SG_ Config_EOE : 0|32@1+ (1,0) [0|4294967295] ""  SystemController,Applications

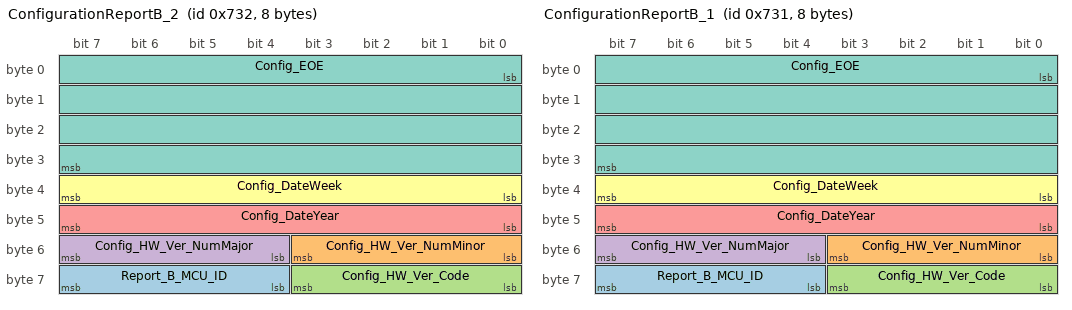
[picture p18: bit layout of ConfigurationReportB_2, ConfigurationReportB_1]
BO_ 1842 ConfigurationReportB_2: 8 PowerModule_2
 SG_ Report_B_MCU_ID : 60|4@1+ (1,0) [0|15] ""  SystemController,Applications
 SG_ Config_HW_Ver_NumMinor : 48|4@1+ (1,0) [0|15] ""  SystemController,Applications
 SG_ Config_HW_Ver_Code : 56|4@1+ (1,0) [0|15] ""  SystemController,Applications
 SG_ Config_HW_Ver_NumMajor : 52|4@1+ (1,0) [0|15] ""  SystemController,Applications
 SG_ Config_DateYear : 40|8@1+ (1,0) [0|255] "YY"  SystemController,Applications
 SG_ Config_DateWeek : 32|8@1+ (1,0) [0|255] "WW"  SystemController,Applications
 SG_ Config_EOE : 0|32@1+ (1,0) [0|4294967295] ""  SystemController,Applications

BO_ 1841 ConfigurationReportB_1: 8 OnBoardCharger_1
 SG_ Report_B_MCU_ID : 60|4@1+ (1,0) [0|15] ""  SystemController,Applications
 SG_ Config_HW_Ver_NumMinor : 48|4@1+ (1,0) [0|15] ""  SystemController,Applications
 SG_ Config_HW_Ver_Code : 56|4@1+ (1,0) [0|15] ""  SystemController,Applications
 SG_ Config_HW_Ver_NumMajor : 52|4@1+ (1,0) [0|15] ""  SystemController,Applications
 SG_ Config_DateYear : 40|8@1+ (1,0) [0|255] "YY"  SystemController,Applications
 SG_ Config_DateWeek : 32|8@1+ (1,0) [0|255] "WW"  SystemController,Applications
 SG_ Config_EOE : 0|32@1+ (1,0) [0|4294967295] ""  SystemController,Applications

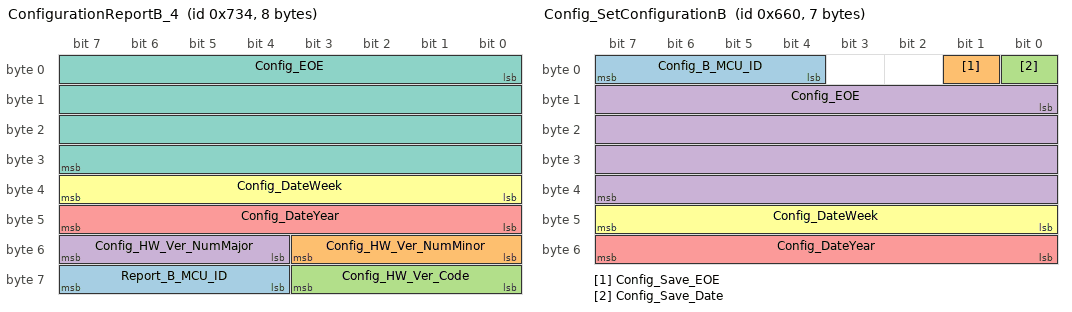
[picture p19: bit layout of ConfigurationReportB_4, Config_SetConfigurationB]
BO_ 1844 ConfigurationReportB_4: 8 PowerModule_4
 SG_ Report_B_MCU_ID : 60|4@1+ (1,0) [0|15] ""  SystemController,Applications
 SG_ Config_HW_Ver_NumMinor : 48|4@1+ (1,0) [0|15] ""  SystemController,Applications
 SG_ Config_HW_Ver_Code : 56|4@1+ (1,0) [0|15] ""  SystemController,Applications
 SG_ Config_HW_Ver_NumMajor : 52|4@1+ (1,0) [0|15] ""  SystemController,Applications
 SG_ Config_DateYear : 40|8@1+ (1,0) [0|255] "YY"  SystemController,Applications
 SG_ Config_DateWeek : 32|8@1+ (1,0) [0|255] "WW"  SystemController,Applications
 SG_ Config_EOE : 0|32@1+ (1,0) [0|4294967295] ""  SystemController,Applications

BO_ 1632 Config_SetConfigurationB: 7 Applications
 SG_ Config_B_MCU_ID : 4|4@1+ (1,0) [0|15] ""  PowerModuleTemplate,OnBoardChargerTemplate,OnBoardCharger_1,WirelessCharger_1,WirelessChargerTemplate
 SG_ Config_Save_EOE : 1|1@1+ (1,0) [0|1] ""  WirelessCharger_1,WirelessChargerTemplate,OnBoardCharger_1,OnBoardChargerTemplate,PowerModuleTemplate
 SG_ Config_Save_Date : 0|1@1+ (1,0) [0|1] ""  WirelessCharger_1,WirelessChargerTemplate,OnBoardCharger_1,OnBoardChargerTemplate,PowerModuleTemplate
 SG_ Config_EOE : 8|32@1+ (1,0) [0|4294967295] ""  WirelessCharger_1,WirelessChargerTemplate,OnBoardCharger_1,OnBoardChargerTemplate,PowerModuleTemplate
 SG_ Config_DateYear : 48|8@1+ (1,0) [0|255] "YY"  WirelessCharger_1,WirelessChargerTemplate,OnBoardCharger_1,OnBoardChargerTemplate,PowerModuleTemplate
 SG_ Config_DateWeek : 40|8@1+ (1,0) [0|255] "WW"  WirelessCharger_1,WirelessChargerTemplate,OnBoardCharger_1,OnBoardChargerTemplate,PowerModuleTemplate

BO_ 842 Mod_DevlogReport_10: 8 PowerModule_10
 SG_ Devlog_ModuleNumber : 32|16@1+ (1,0) [0|0] ""  SystemController,Applications
 SG_ Devlog_LineNumber : 16|16@1+ (1,0) [0|0] ""  SystemController,Applications
 SG_ Devlog_EventNumber : 0|16@1+ (1,0) [0|65535] ""  SystemController,Applications
 SG_ Devlog_Data_L : 48|16@1+ (1,0) [0|0] ""  SystemController,Applications

BO_ 841 Mod_DevlogReport_9: 8 PowerModule_9
 SG_ Devlog_ModuleNumber : 32|16@1+ (1,0) [0|0] ""  SystemController,Applications
 SG_ Devlog_LineNumber : 16|16@1+ (1,0) [0|0] ""  SystemController,Applications
 SG_ Devlog_EventNumber : 0|16@1+ (1,0) [0|65535] ""  SystemController,Applications
 SG_ Devlog_Data_L : 48|16@1+ (1,0) [0|0] ""  SystemController,Applications

BO_ 840 Mod_DevlogReport_8: 8 PowerModule_8
 SG_ Devlog_ModuleNumber : 32|16@1+ (1,0) [0|0] ""  SystemController,Applications
 SG_ Devlog_LineNumber : 16|16@1+ (1,0) [0|0] ""  SystemController,Applications
 SG_ Devlog_EventNumber : 0|16@1+ (1,0) [0|65535] ""  SystemController,Applications
 SG_ Devlog_Data_L : 48|16@1+ (1,0) [0|0] ""  SystemController,Applications

BO_ 839 Mod_DevlogReport_7: 8 PowerModule_7
 SG_ Devlog_ModuleNumber : 32|16@1+ (1,0) [0|0] ""  SystemController,Applications
 SG_ Devlog_LineNumber : 16|16@1+ (1,0) [0|0] ""  SystemController,Applications
 SG_ Devlog_EventNumber : 0|16@1+ (1,0) [0|65535] ""  SystemController,Applications
 SG_ Devlog_Data_L : 48|16@1+ (1,0) [0|0] ""  SystemController,Applications

BO_ 838 Mod_DevlogReport_6: 8 PowerModule_6
 SG_ Devlog_ModuleNumber : 32|16@1+ (1,0) [0|0] ""  SystemController,Applications
 SG_ Devlog_LineNumber : 16|16@1+ (1,0) [0|0] ""  SystemController,Applications
 SG_ Devlog_EventNumber : 0|16@1+ (1,0) [0|65535] ""  SystemController,Applications
 SG_ Devlog_Data_L : 48|16@1+ (1,0) [0|0] ""  SystemController,Applications

BO_ 837 Mod_DevlogReport_5: 8 PowerModule_5
 SG_ Devlog_ModuleNumber : 32|16@1+ (1,0) [0|0] ""  SystemController,Applications
 SG_ Devlog_LineNumber : 16|16@1+ (1,0) [0|0] ""  SystemController,Applications
 SG_ Devlog_EventNumber : 0|16@1+ (1,0) [0|65535] ""  SystemController,Applications
 SG_ Devlog_Data_L : 48|16@1+ (1,0) [0|0] ""  SystemController,Applications

BO_ 836 Mod_DevlogReport_4: 8 PowerModule_4
 SG_ Devlog_ModuleNumber : 32|16@1+ (1,0) [0|0] ""  SystemController,Applications
 SG_ Devlog_LineNumber : 16|16@1+ (1,0) [0|0] ""  SystemController,Applications
 SG_ Devlog_EventNumber : 0|16@1+ (1,0) [0|65535] ""  SystemController,Applications
 SG_ Devlog_Data_L : 48|16@1+ (1,0) [0|0] ""  SystemController,Applications

BO_ 835 Mod_DevlogReport_3: 8 PowerModule_3
 SG_ Devlog_ModuleNumber : 32|16@1+ (1,0) [0|0] ""  SystemController,Applications
 SG_ Devlog_LineNumber : 16|16@1+ (1,0) [0|0] ""  SystemController,Applications
 SG_ Devlog_EventNumber : 0|16@1+ (1,0) [0|65535] ""  SystemController,Applications
 SG_ Devlog_Data_L : 48|16@1+ (1,0) [0|0] ""  SystemController,Applications

BO_ 1802 Mod_Calibration_StatusReport_10: 4 PowerModule_10
 SG_ Calib_MeasurementType : 24|8@1+ (1,0) [0|0] ""  SystemController,Applications
 SG_ Calib_Status : 0|8@1+ (1,0) [0|255] ""  SystemController,Applications
 SG_ Calib_AdcSample : 8|16@1+ (1,0) [0|65535] ""  SystemController,Applications

BO_ 1801 Mod_Calibration_StatusReport_9: 4 PowerModule_9
 SG_ Calib_MeasurementType : 24|8@1+ (1,0) [0|0] ""  SystemController,Applications
 SG_ Calib_Status : 0|8@1+ (1,0) [0|255] ""  SystemController,Applications
 SG_ Calib_AdcSample : 8|16@1+ (1,0) [0|65535] ""  SystemController,Applications

BO_ 1800 Mod_Calibration_StatusReport_8: 4 PowerModule_8
 SG_ Calib_MeasurementType : 24|8@1+ (1,0) [0|0] ""  SystemController,Applications
 SG_ Calib_Status : 0|8@1+ (1,0) [0|255] ""  SystemController,Applications
 SG_ Calib_AdcSample : 8|16@1+ (1,0) [0|65535] ""  SystemController,Applications

BO_ 1799 Mod_Calibration_StatusReport_7: 4 PowerModule_7
 SG_ Calib_MeasurementType : 24|8@1+ (1,0) [0|0] ""  SystemController,Applications
 SG_ Calib_Status : 0|8@1+ (1,0) [0|255] ""  SystemController,Applications
 SG_ Calib_AdcSample : 8|16@1+ (1,0) [0|65535] ""  SystemController,Applications

BO_ 1798 Mod_Calibration_StatusReport_6: 4 PowerModule_6
 SG_ Calib_MeasurementType : 24|8@1+ (1,0) [0|0] ""  SystemController,Applications
 SG_ Calib_Status : 0|8@1+ (1,0) [0|255] ""  SystemController,Applications
 SG_ Calib_AdcSample : 8|16@1+ (1,0) [0|65535] ""  SystemController,Applications

BO_ 794 ModulePowerMeasurementsSlow_10: 5 PowerModule_10
 SG_ Report_StatusOfPowerSlow : 39|1@1+ (1,0) [0|1] ""  Applications
 SG_ Report_StatusOfFaultSlow : 38|1@1+ (1,0) [0|1] ""  Applications
 SG_ Report_Meas_Voltage_Slow : 0|20@1+ (0.001,0) [0|1048.575] "Volts"  Applications
 SG_ Report_Meas_Current_Slow : 20|18@1+ (0.001,0) [0|262.143] "Amps"  Applications

BO_ 793 ModulePowerMeasurementsSlow_9: 5 PowerModule_9
 SG_ Report_StatusOfPowerSlow : 39|1@1+ (1,0) [0|1] ""  Applications
 SG_ Report_StatusOfFaultSlow : 38|1@1+ (1,0) [0|1] ""  Applications
 SG_ Report_Meas_Voltage_Slow : 0|20@1+ (0.001,0) [0|1048.575] "Volts"  Applications
 SG_ Report_Meas_Current_Slow : 20|18@1+ (0.001,0) [0|262.143] "Amps"  Applications

BO_ 792 ModulePowerMeasurementsSlow_8: 5 PowerModule_8
 SG_ Report_StatusOfPowerSlow : 39|1@1+ (1,0) [0|1] ""  Applications
 SG_ Report_StatusOfFaultSlow : 38|1@1+ (1,0) [0|1] ""  Applications
 SG_ Report_Meas_Voltage_Slow : 0|20@1+ (0.001,0) [0|1048.575] "Volts"  Applications
 SG_ Report_Meas_Current_Slow : 20|18@1+ (0.001,0) [0|262.143] "Amps"  Applications

BO_ 791 ModulePowerMeasurementsSlow_7: 5 PowerModule_7
 SG_ Report_StatusOfPowerSlow : 39|1@1+ (1,0) [0|1] ""  Applications
 SG_ Report_StatusOfFaultSlow : 38|1@1+ (1,0) [0|1] ""  Applications
 SG_ Report_Meas_Voltage_Slow : 0|20@1+ (0.001,0) [0|1048.575] "Volts"  Applications
 SG_ Report_Meas_Current_Slow : 20|18@1+ (0.001,0) [0|262.143] "Amps"  Applications

BO_ 790 ModulePowerMeasurementsSlow_6: 5 PowerModule_6
 SG_ Report_StatusOfPowerSlow : 39|1@1+ (1,0) [0|1] ""  Applications
 SG_ Report_StatusOfFaultSlow : 38|1@1+ (1,0) [0|1] ""  Applications
 SG_ Report_Meas_Voltage_Slow : 0|20@1+ (0.001,0) [0|1048.575] "Volts"  Applications
 SG_ Report_Meas_Current_Slow : 20|18@1+ (0.001,0) [0|262.143] "Amps"  Applications

BO_ 789 ModulePowerMeasurementsSlow_5: 5 PowerModule_5
 SG_ Report_StatusOfPowerSlow : 39|1@1+ (1,0) [0|1] ""  Applications
 SG_ Report_StatusOfFaultSlow : 38|1@1+ (1,0) [0|1] ""  Applications
 SG_ Report_Meas_Voltage_Slow : 0|20@1+ (0.001,0) [0|1048.575] "Volts"  Applications
 SG_ Report_Meas_Current_Slow : 20|18@1+ (0.001,0) [0|262.143] "Amps"  Applications

BO_ 788 ModulePowerMeasurementsSlow_4: 5 PowerModule_4
 SG_ Report_StatusOfPowerSlow : 39|1@1+ (1,0) [0|1] ""  Applications
 SG_ Report_StatusOfFaultSlow : 38|1@1+ (1,0) [0|1] ""  Applications
 SG_ Report_Meas_Voltage_Slow : 0|20@1+ (0.001,0) [0|1048.575] "Volts"  Applications
 SG_ Report_Meas_Current_Slow : 20|18@1+ (0.001,0) [0|262.143] "Amps"  Applications

BO_ 787 ModulePowerMeasurementsSlow_3: 5 PowerModule_3
 SG_ Report_StatusOfPowerSlow : 39|1@1+ (1,0) [0|1] ""  Applications
 SG_ Report_StatusOfFaultSlow : 38|1@1+ (1,0) [0|1] ""  Applications
 SG_ Report_Meas_Voltage_Slow : 0|20@1+ (0.001,0) [0|1048.575] "Volts"  Applications
 SG_ Report_Meas_Current_Slow : 20|18@1+ (0.001,0) [0|262.143] "Amps"  Applications

BO_ 786 ModulePowerMeasurementsSlow_2: 5 PowerModule_2
 SG_ Report_StatusOfPowerSlow : 39|1@1+ (1,0) [0|1] ""  Applications
 SG_ Report_StatusOfFaultSlow : 38|1@1+ (1,0) [0|1] ""  Applications
 SG_ Report_Meas_Voltage_Slow : 0|20@1+ (0.001,0) [0|1048.575] "Volts"  Applications
 SG_ Report_Meas_Current_Slow : 20|18@1+ (0.001,0) [0|262.143] "Amps"  Applications

BO_ 785 ModulePowerMeasurementsSlow_1: 5 PowerModule_1
 SG_ Report_StatusOfPowerSlow : 39|1@1+ (1,0) [0|1] ""  Applications
 SG_ Report_StatusOfFaultSlow : 38|1@1+ (1,0) [0|1] ""  Applications
 SG_ Report_Meas_Voltage_Slow : 0|20@1+ (0.001,0) [0|1048.575] "Volts"  Applications
 SG_ Report_Meas_Current_Slow : 20|18@1+ (0.001,0) [0|262.143] "Amps"  Applications

BO_ 784 ModulePowerMeasurementsSlowT: 5 PowerModuleTemplate
 SG_ Report_StatusOfPowerSlow : 39|1@1+ (1,0) [0|1] "" Vector__XXX
 SG_ Report_StatusOfFaultSlow : 38|1@1+ (1,0) [0|1] "" Vector__XXX
 SG_ Report_Meas_Voltage_Slow : 0|20@1+ (0.001,0) [0|1048.575] "Volts" Vector__XXX
 SG_ Report_Meas_Current_Slow : 20|18@1+ (0.001,0) [0|262.143] "Amps" Vector__XXX

BO_ 1818 ModulePowerLimits_10: 6 PowerModule_10
 SG_ Limit_Power : 32|16@1+ (1,0) [0|0] "W"  Applications,SystemController
 SG_ Limit_MinVoltageForMaxPower : 24|8@1+ (1,0) [0|0] "V"  Applications,SystemController
 SG_ Limit_MaxVoltage : 16|8@1+ (1,0) [0|0] "V"  Applications,SystemController
 SG_ Limit_MaxCurrent : 0|16@1- (0.1,0) [0|0] "A"  Applications,SystemController

BO_ 1817 ModulePowerLimits_9: 6 PowerModule_9
 SG_ Limit_Power : 32|16@1+ (1,0) [0|0] "W"  Applications,SystemController
 SG_ Limit_MinVoltageForMaxPower : 24|8@1+ (1,0) [0|0] "V"  Applications,SystemController
 SG_ Limit_MaxVoltage : 16|8@1+ (1,0) [0|0] "V"  Applications,SystemController
 SG_ Limit_MaxCurrent : 0|16@1- (0.1,0) [0|0] "A"  Applications,SystemController

BO_ 1816 ModulePowerLimits_8: 6 PowerModule_8
 SG_ Limit_Power : 32|16@1+ (1,0) [0|0] "W"  Applications,SystemController
 SG_ Limit_MinVoltageForMaxPower : 24|8@1+ (1,0) [0|0] "V"  Applications,SystemController
 SG_ Limit_MaxVoltage : 16|8@1+ (1,0) [0|0] "V"  Applications,SystemController
 SG_ Limit_MaxCurrent : 0|16@1- (0.1,0) [0|0] "A"  Applications,SystemController

BO_ 1815 ModulePowerLimits_7: 6 PowerModule_7
 SG_ Limit_Power : 32|16@1+ (1,0) [0|0] "W"  Applications,SystemController
 SG_ Limit_MinVoltageForMaxPower : 24|8@1+ (1,0) [0|0] "V"  Applications,SystemController
 SG_ Limit_MaxVoltage : 16|8@1+ (1,0) [0|0] "V"  Applications,SystemController
 SG_ Limit_MaxCurrent : 0|16@1- (0.1,0) [0|0] "A"  Applications,SystemController

BO_ 1814 ModulePowerLimits_6: 6 PowerModule_6
 SG_ Limit_Power : 32|16@1+ (1,0) [0|0] "W"  Applications,SystemController
 SG_ Limit_MinVoltageForMaxPower : 24|8@1+ (1,0) [0|0] "V"  Applications,SystemController
 SG_ Limit_MaxVoltage : 16|8@1+ (1,0) [0|0] "V"  Applications,SystemController
 SG_ Limit_MaxCurrent : 0|16@1- (0.1,0) [0|0] "A"  Applications,SystemController

BO_ 1813 ModulePowerLimits_5: 6 PowerModule_5
 SG_ Limit_Power : 32|16@1+ (1,0) [0|0] "W"  Applications,SystemController
 SG_ Limit_MinVoltageForMaxPower : 24|8@1+ (1,0) [0|0] "V"  Applications,SystemController
 SG_ Limit_MaxVoltage : 16|8@1+ (1,0) [0|0] "V"  Applications,SystemController
 SG_ Limit_MaxCurrent : 0|16@1- (0.1,0) [0|0] "A"  Applications,SystemController

BO_ 1812 ModulePowerLimits_4: 6 PowerModule_4
 SG_ Limit_Power : 32|16@1+ (1,0) [0|0] "W"  Applications,SystemController
 SG_ Limit_MinVoltageForMaxPower : 24|8@1+ (1,0) [0|0] "V"  Applications,SystemController
 SG_ Limit_MaxVoltage : 16|8@1+ (1,0) [0|0] "V"  Applications,SystemController
 SG_ Limit_MaxCurrent : 0|16@1- (0.1,0) [0|0] "A"  Applications,SystemController

BO_ 1811 ModulePowerLimits_3: 6 PowerModule_3
 SG_ Limit_Power : 32|16@1+ (1,0) [0|0] "W"  Applications,SystemController
 SG_ Limit_MinVoltageForMaxPower : 24|8@1+ (1,0) [0|0] "V"  Applications,SystemController
 SG_ Limit_MaxVoltage : 16|8@1+ (1,0) [0|0] "V"  Applications,SystemController
 SG_ Limit_MaxCurrent : 0|16@1- (0.1,0) [0|0] "A"  Applications,SystemController

BO_ 1810 ModulePowerLimits_2: 6 PowerModule_2
 SG_ Limit_Power : 32|16@1+ (1,0) [0|0] "W"  Applications,SystemController
 SG_ Limit_MinVoltageForMaxPower : 24|8@1+ (1,0) [0|0] "V"  Applications,SystemController
 SG_ Limit_MaxVoltage : 16|8@1+ (1,0) [0|0] "V"  Applications,SystemController
 SG_ Limit_MaxCurrent : 0|16@1- (0.1,0) [0|0] "A"  Applications,SystemController

BO_ 1809 ModulePowerLimits_1: 6 PowerModule_1
 SG_ Limit_Power : 32|16@1+ (1,0) [0|0] "W"  Applications,SystemController
 SG_ Limit_MinVoltageForMaxPower : 24|8@1+ (1,0) [0|0] "V"  Applications,SystemController
 SG_ Limit_MaxVoltage : 16|8@1+ (1,0) [0|0] "V"  Applications,SystemController
 SG_ Limit_MaxCurrent : 0|16@1- (0.1,0) [0|0] "A"  Applications,SystemController

BO_ 1808 ModulePowerLimits_T: 6 PowerModuleTemplate
 SG_ Limit_Power : 32|16@1+ (1,0) [0|0] "W" Vector__XXX
 SG_ Limit_MinVoltageForMaxPower : 24|8@1+ (1,0) [0|0] "V" Vector__XXX
 SG_ Limit_MaxVoltage : 16|8@1+ (1,0) [0|0] "V" Vector__XXX
 SG_ Limit_MaxCurrent : 0|16@1- (0.1,0) [0|0] "A" Vector__XXX

BO_ 1434 ModuleLifeReportJ_10: 8 PowerModule_10
 SG_ Report_Life_TempDeratingTime : 32|32@1+ (1,0) [0|4294967295] "Seconds"  Applications,SystemController
 SG_ Report_Life_PowDeratingTime : 0|32@1+ (1,0) [0|4294967295] "Seconds"  Applications,SystemController

BO_ 1433 ModuleLifeReportJ_9: 8 PowerModule_9
 SG_ Report_Life_TempDeratingTime : 32|32@1+ (1,0) [0|4294967295] "Seconds"  Applications,SystemController
 SG_ Report_Life_PowDeratingTime : 0|32@1+ (1,0) [0|4294967295] "Seconds"  Applications,SystemController

BO_ 1432 ModuleLifeReportJ_8: 8 PowerModule_8
 SG_ Report_Life_TempDeratingTime : 32|32@1+ (1,0) [0|4294967295] "Seconds"  Applications,SystemController
 SG_ Report_Life_PowDeratingTime : 0|32@1+ (1,0) [0|4294967295] "Seconds"  Applications,SystemController
